[part 1 of 4: packages /cif_swcCanInterface to /cif_swcCanInterface/CANBus_CAN_RT/applicationDataTypes]
AUTOSAR XML (schema 4-1-3)
standard types defined: boolean, float32, float64, sint16, sint32, sint64, sint8, uint16, uint32, uint64, uint8
package /cif_swcCanInterface
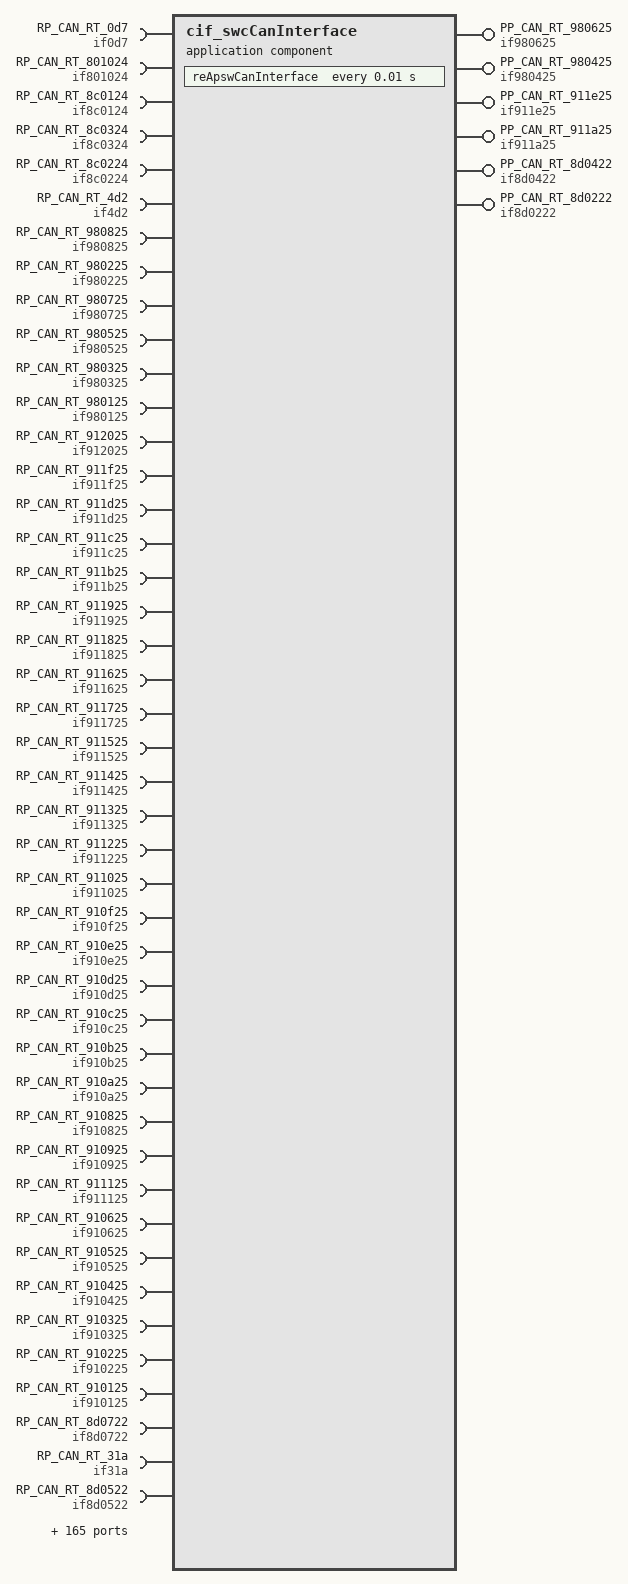
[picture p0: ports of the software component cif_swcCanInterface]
  application sw component type cif_swcCanInterface  # This SW-C may serve as interface to the low level CAN communication. It is connected to the ISignals of the COM component. Its runnable can read and write all in- and output signals and can either process them or delegate them to other SW-Cs
    6 x provide port:
      PP_CAN_RT_980625: provided-interface=if980625  # This is a provided port for all signals of outbound CAN frame RT_IRTemp_Temp_RL_2, 9963045 (0x980625). The data elements of this port will typically be mapped to the related outbound ISignals of the COM component.
      PP_CAN_RT_980425: provided-interface=if980425  # This is a provided port for all signals of outbound CAN frame RT_IRTemp_Temp_FR_2, 9962533 (0x980425). The data elements of this port will typically be mapped to the related outbound ISignals of the COM component.
      PP_CAN_RT_911e25: provided-interface=if911e25  # This is a provided port for all signals of outbound CAN frame RT_IRTemp_Temp_30, 9510437 (0x911e25). The data elements of this port will typically be mapped to the related outbound ISignals of the COM component.
      PP_CAN_RT_911a25: provided-interface=if911a25  # This is a provided port for all signals of outbound CAN frame RT_IRTemp_Temp_26, 9509413 (0x911a25). The data elements of this port will typically be mapped to the related outbound ISignals of the COM component.
      PP_CAN_RT_8d0422: provided-interface=if8d0422  # This is a provided port for all signals of outbound CAN frame RT_SB_Trig_Forward_Dist, 9241634 (0x8d0422). The data elements of this port will typically be mapped to the related outbound ISignals of the COM component.
      PP_CAN_RT_8d0222: provided-interface=if8d0222  # This is a provided port for all signals of outbound CAN frame RT_SB_Trig_Accel, 9241122 (0x8d0222). The data elements of this port will typically be mapped to the related outbound ISignals of the COM component.
    209 x require port:
      RP_CAN_RT_0d7: required-interface=if0d7  # This is a required port for all signals of inbound CAN frame RT_SB_INS_Vel_Body_Axes, 215 (0x0d7). The data elements of this port will typically be mapped to the related inbound ISignals of the COM component.
      RP_CAN_RT_801024: required-interface=if801024  # This is a required port for all signals of inbound CAN frame RT_DL1MK3_Speed, 8392740 (0x801024). The data elements of this port will typically be mapped to the related inbound ISignals of the COM component.
      RP_CAN_RT_8c0124: required-interface=if8c0124  # This is a required port for all signals of inbound CAN frame RT_DL1MK3_GPS_Time, 9175332 (0x8c0124). The data elements of this port will typically be mapped to the related inbound ISignals of the COM component.
      RP_CAN_RT_8c0324: required-interface=if8c0324  # This is a required port for all signals of inbound CAN frame RT_DL1MK3_GPS_Pos_LLH_2, 9175844 (0x8c0324). The data elements of this port will typically be mapped to the related inbound ISignals of the COM component.
      RP_CAN_RT_8c0224: required-interface=if8c0224  # This is a required port for all signals of inbound CAN frame RT_DL1MK3_GPS_Pos_LLH_1, 9175588 (0x8c0224). The data elements of this port will typically be mapped to the related inbound ISignals of the COM component.
      RP_CAN_RT_4d2: required-interface=if4d2  # This is a required port for all signals of inbound CAN frame RT_DL1MK3_GPS_Speed, 1234 (0x4d2). The data elements of this port will typically be mapped to the related inbound ISignals of the COM component.
      RP_CAN_RT_980825: required-interface=if980825  # This is a required port for all signals of inbound CAN frame RT_IRTemp_Temp_RR_2, 9963557 (0x980825). The data elements of this port will typically be mapped to the related inbound ISignals of the COM component.
      RP_CAN_RT_980225: required-interface=if980225  # This is a required port for all signals of inbound CAN frame RT_IRTemp_Temp_FL_2, 9962021 (0x980225). The data elements of this port will typically be mapped to the related inbound ISignals of the COM component.
      RP_CAN_RT_980725: required-interface=if980725  # This is a required port for all signals of inbound CAN frame RT_IRTemp_Temp_RR_1, 9963301 (0x980725). The data elements of this port will typically be mapped to the related inbound ISignals of the COM component.
      RP_CAN_RT_980525: required-interface=if980525  # This is a required port for all signals of inbound CAN frame RT_IRTemp_Temp_RL_1, 9962789 (0x980525). The data elements of this port will typically be mapped to the related inbound ISignals of the COM component.
      RP_CAN_RT_980325: required-interface=if980325  # This is a required port for all signals of inbound CAN frame RT_IRTemp_Temp_FR_1, 9962277 (0x980325). The data elements of this port will typically be mapped to the related inbound ISignals of the COM component.
      RP_CAN_RT_980125: required-interface=if980125  # This is a required port for all signals of inbound CAN frame RT_IRTemp_Temp_FL_1, 9961765 (0x980125). The data elements of this port will typically be mapped to the related inbound ISignals of the COM component.
      RP_CAN_RT_912025: required-interface=if912025  # This is a required port for all signals of inbound CAN frame RT_IRTemp_Temp_32, 9510949 (0x912025). The data elements of this port will typically be mapped to the related inbound ISignals of the COM component.
      RP_CAN_RT_911f25: required-interface=if911f25  # This is a required port for all signals of inbound CAN frame RT_IRTemp_Temp_31, 9510693 (0x911f25). The data elements of this port will typically be mapped to the related inbound ISignals of the COM component.
      RP_CAN_RT_911d25: required-interface=if911d25  # This is a required port for all signals of inbound CAN frame RT_IRTemp_Temp_29, 9510181 (0x911d25). The data elements of this port will typically be mapped to the related inbound ISignals of the COM component.
      RP_CAN_RT_911c25: required-interface=if911c25  # This is a required port for all signals of inbound CAN frame RT_IRTemp_Temp_28, 9509925 (0x911c25). The data elements of this port will typically be mapped to the related inbound ISignals of the COM component.
      RP_CAN_RT_911b25: required-interface=if911b25  # This is a required port for all signals of inbound CAN frame RT_IRTemp_Temp_27, 9509669 (0x911b25). The data elements of this port will typically be mapped to the related inbound ISignals of the COM component.
      RP_CAN_RT_911925: required-interface=if911925  # This is a required port for all signals of inbound CAN frame RT_IRTemp_Temp_25, 9509157 (0x911925). The data elements of this port will typically be mapped to the related inbound ISignals of the COM component.
      RP_CAN_RT_911825: required-interface=if911825  # This is a required port for all signals of inbound CAN frame RT_IRTemp_Temp_24, 9508901 (0x911825). The data elements of this port will typically be mapped to the related inbound ISignals of the COM component.
      RP_CAN_RT_911625: required-interface=if911625  # This is a required port for all signals of inbound CAN frame RT_IRTemp_Temp_22, 9508389 (0x911625). The data elements of this port will typically be mapped to the related inbound ISignals of the COM component.
      RP_CAN_RT_911725: required-interface=if911725  # This is a required port for all signals of inbound CAN frame RT_IRTemp_Temp_23, 9508645 (0x911725). The data elements of this port will typically be mapped to the related inbound ISignals of the COM component.
      RP_CAN_RT_911525: required-interface=if911525  # This is a required port for all signals of inbound CAN frame RT_IRTemp_Temp_21, 9508133 (0x911525). The data elements of this port will typically be mapped to the related inbound ISignals of the COM component.
      RP_CAN_RT_911425: required-interface=if911425  # This is a required port for all signals of inbound CAN frame RT_IRTemp_Temp_20, 9507877 (0x911425). The data elements of this port will typically be mapped to the related inbound ISignals of the COM component.
      RP_CAN_RT_911325: required-interface=if911325  # This is a required port for all signals of inbound CAN frame RT_IRTemp_Temp_19, 9507621 (0x911325). The data elements of this port will typically be mapped to the related inbound ISignals of the COM component.
      RP_CAN_RT_911225: required-interface=if911225  # This is a required port for all signals of inbound CAN frame RT_IRTemp_Temp_18, 9507365 (0x911225). The data elements of this port will typically be mapped to the related inbound ISignals of the COM component.
      RP_CAN_RT_911025: required-interface=if911025  # This is a required port for all signals of inbound CAN frame RT_IRTemp_Temp_16, 9506853 (0x911025). The data elements of this port will typically be mapped to the related inbound ISignals of the COM component.
      RP_CAN_RT_910f25: required-interface=if910f25  # This is a required port for all signals of inbound CAN frame RT_IRTemp_Temp_15, 9506597 (0x910f25). The data elements of this port will typically be mapped to the related inbound ISignals of the COM component.
      RP_CAN_RT_910e25: required-interface=if910e25  # This is a required port for all signals of inbound CAN frame RT_IRTemp_Temp_14, 9506341 (0x910e25). The data elements of this port will typically be mapped to the related inbound ISignals of the COM component.
      RP_CAN_RT_910d25: required-interface=if910d25  # This is a required port for all signals of inbound CAN frame RT_IRTemp_Temp_13, 9506085 (0x910d25). The data elements of this port will typically be mapped to the related inbound ISignals of the COM component.
      RP_CAN_RT_910c25: required-interface=if910c25  # This is a required port for all signals of inbound CAN frame RT_IRTemp_Temp_12, 9505829 (0x910c25). The data elements of this port will typically be mapped to the related inbound ISignals of the COM component.
      RP_CAN_RT_910b25: required-interface=if910b25  # This is a required port for all signals of inbound CAN frame RT_IRTemp_Temp_11, 9505573 (0x910b25). The data elements of this port will typically be mapped to the related inbound ISignals of the COM component.
      RP_CAN_RT_910a25: required-interface=if910a25  # This is a required port for all signals of inbound CAN frame RT_IRTemp_Temp_10, 9505317 (0x910a25). The data elements of this port will typically be mapped to the related inbound ISignals of the COM component.
      RP_CAN_RT_910825: required-interface=if910825  # This is a required port for all signals of inbound CAN frame RT_IRTemp_Temp_8, 9504805 (0x910825). The data elements of this port will typically be mapped to the related inbound ISignals of the COM component.
      RP_CAN_RT_910925: required-interface=if910925  # This is a required port for all signals of inbound CAN frame RT_IRTemp_Temp_9, 9505061 (0x910925). The data elements of this port will typically be mapped to the related inbound ISignals of the COM component.
      RP_CAN_RT_911125: required-interface=if911125  # This is a required port for all signals of inbound CAN frame RT_IRTemp_Temp_17, 9507109 (0x911125). The data elements of this port will typically be mapped to the related inbound ISignals of the COM component.
      RP_CAN_RT_910625: required-interface=if910625  # This is a required port for all signals of inbound CAN frame RT_IRTemp_Temp_6, 9504293 (0x910625). The data elements of this port will typically be mapped to the related inbound ISignals of the COM component.
      RP_CAN_RT_910525: required-interface=if910525  # This is a required port for all signals of inbound CAN frame RT_IRTemp_Temp_5, 9504037 (0x910525). The data elements of this port will typically be mapped to the related inbound ISignals of the COM component.
      RP_CAN_RT_910425: required-interface=if910425  # This is a required port for all signals of inbound CAN frame RT_IRTemp_Temp_4, 9503781 (0x910425). The data elements of this port will typically be mapped to the related inbound ISignals of the COM component.
      RP_CAN_RT_910325: required-interface=if910325  # This is a required port for all signals of inbound CAN frame RT_IRTemp_Temp_3, 9503525 (0x910325). The data elements of this port will typically be mapped to the related inbound ISignals of the COM component.
      RP_CAN_RT_910225: required-interface=if910225  # This is a required port for all signals of inbound CAN frame RT_IRTemp_Temp_2, 9503269 (0x910225). The data elements of this port will typically be mapped to the related inbound ISignals of the COM component.
      RP_CAN_RT_910125: required-interface=if910125  # This is a required port for all signals of inbound CAN frame RT_IRTemp_Temp_1, 9503013 (0x910125). The data elements of this port will typically be mapped to the related inbound ISignals of the COM component.
      RP_CAN_RT_8d0722: required-interface=if8d0722  # This is a required port for all signals of inbound CAN frame RT_SB_Trig_Final_Condition, 9242402 (0x8d0722). The data elements of this port will typically be mapped to the related inbound ISignals of the COM component.
      RP_CAN_RT_31a: required-interface=if31a  # This is a required port for all signals of inbound CAN frame RT_SB_Trig_Initial_Condition, 794 (0x31a). The data elements of this port will typically be mapped to the related inbound ISignals of the COM component.
      RP_CAN_RT_8d0522: required-interface=if8d0522  # This is a required port for all signals of inbound CAN frame RT_SB_Trig_Direct_Dist, 9241890 (0x8d0522). The data elements of this port will typically be mapped to the related inbound ISignals of the COM component.
      RP_CAN_RT_8d0322: required-interface=if8d0322  # This is a required port for all signals of inbound CAN frame RT_SB_Trig_Path_Dist, 9241378 (0x8d0322). The data elements of this port will typically be mapped to the related inbound ISignals of the COM component.
      RP_CAN_RT_960b24: required-interface=if960b24  # This is a required port for all signals of inbound CAN frame RT_DL1MK3_Measure_Time_11, 9833252 (0x960b24). The data elements of this port will typically be mapped to the related inbound ISignals of the COM component.
      RP_CAN_RT_960a24: required-interface=if960a24  # This is a required port for all signals of inbound CAN frame RT_DL1MK3_Measure_Time_10, 9832996 (0x960a24). The data elements of this port will typically be mapped to the related inbound ISignals of the COM component.
      RP_CAN_RT_960924: required-interface=if960924  # This is a required port for all signals of inbound CAN frame RT_DL1MK3_Measure_Time_9, 9832740 (0x960924). The data elements of this port will typically be mapped to the related inbound ISignals of the COM component.
      RP_CAN_RT_960824: required-interface=if960824  # This is a required port for all signals of inbound CAN frame RT_DL1MK3_Measure_Time_8, 9832484 (0x960824). The data elements of this port will typically be mapped to the related inbound ISignals of the COM component.
      RP_CAN_RT_960724: required-interface=if960724  # This is a required port for all signals of inbound CAN frame RT_DL1MK3_Measure_Time_7, 9832228 (0x960724). The data elements of this port will typically be mapped to the related inbound ISignals of the COM component.
      RP_CAN_RT_960624: required-interface=if960624  # This is a required port for all signals of inbound CAN frame RT_DL1MK3_Measure_Time_6, 9831972 (0x960624). The data elements of this port will typically be mapped to the related inbound ISignals of the COM component.
      RP_CAN_RT_960524: required-interface=if960524  # This is a required port for all signals of inbound CAN frame RT_DL1MK3_Measure_Time_5, 9831716 (0x960524). The data elements of this port will typically be mapped to the related inbound ISignals of the COM component.
      RP_CAN_RT_960424: required-interface=if960424  # This is a required port for all signals of inbound CAN frame RT_DL1MK3_Measure_Time_4, 9831460 (0x960424). The data elements of this port will typically be mapped to the related inbound ISignals of the COM component.
      RP_CAN_RT_960324: required-interface=if960324  # This is a required port for all signals of inbound CAN frame RT_DL1MK3_Measure_Time_3, 9831204 (0x960324). The data elements of this port will typically be mapped to the related inbound ISignals of the COM component.
      RP_CAN_RT_960224: required-interface=if960224  # This is a required port for all signals of inbound CAN frame RT_DL1MK3_Measure_Time_2, 9830948 (0x960224). The data elements of this port will typically be mapped to the related inbound ISignals of the COM component.
      RP_CAN_RT_960124: required-interface=if960124  # This is a required port for all signals of inbound CAN frame RT_DL1MK3_Measure_Time_1, 9830692 (0x960124). The data elements of this port will typically be mapped to the related inbound ISignals of the COM component.
      RP_CAN_RT_950c24: required-interface=if950c24  # This is a required port for all signals of inbound CAN frame RT_DL1MK3_RPM, 9767972 (0x950c24). The data elements of this port will typically be mapped to the related inbound ISignals of the COM component.
      RP_CAN_RT_950b24: required-interface=if950b24  # This is a required port for all signals of inbound CAN frame RT_DL1MK3_Freq_4, 9767716 (0x950b24). The data elements of this port will typically be mapped to the related inbound ISignals of the COM component.
      RP_CAN_RT_950a24: required-interface=if950a24  # This is a required port for all signals of inbound CAN frame RT_DL1MK3_Freq_3, 9767460 (0x950a24). The data elements of this port will typically be mapped to the related inbound ISignals of the COM component.
      RP_CAN_RT_950924: required-interface=if950924  # This is a required port for all signals of inbound CAN frame RT_DL1MK3_Freq_2, 9767204 (0x950924). The data elements of this port will typically be mapped to the related inbound ISignals of the COM component.
      RP_CAN_RT_970324: required-interface=if970324  # This is a required port for all signals of inbound CAN frame RT_DL1MK3_Misc_3, 9896740 (0x970324). The data elements of this port will typically be mapped to the related inbound ISignals of the COM component.
      RP_CAN_RT_970224: required-interface=if970224  # This is a required port for all signals of inbound CAN frame RT_DL1MK3_Misc_2, 9896484 (0x970224). The data elements of this port will typically be mapped to the related inbound ISignals of the COM component.
      RP_CAN_RT_970124: required-interface=if970124  # This is a required port for all signals of inbound CAN frame RT_DL1MK3_Misc_1, 9896228 (0x970124). The data elements of this port will typically be mapped to the related inbound ISignals of the COM component.
      RP_CAN_RT_941f24: required-interface=if941f24  # This is a required port for all signals of inbound CAN frame RT_DL1MK3_Aux_31, 9707300 (0x941f24). The data elements of this port will typically be mapped to the related inbound ISignals of the COM component.
      RP_CAN_RT_941e24: required-interface=if941e24  # This is a required port for all signals of inbound CAN frame RT_DL1MK3_Aux_30, 9707044 (0x941e24). The data elements of this port will typically be mapped to the related inbound ISignals of the COM component.
      RP_CAN_RT_941d24: required-interface=if941d24  # This is a required port for all signals of inbound CAN frame RT_DL1MK3_Aux_29, 9706788 (0x941d24). The data elements of this port will typically be mapped to the related inbound ISignals of the COM component.
      RP_CAN_RT_941c24: required-interface=if941c24  # This is a required port for all signals of inbound CAN frame RT_DL1MK3_Aux_28, 9706532 (0x941c24). The data elements of this port will typically be mapped to the related inbound ISignals of the COM component.
      RP_CAN_RT_941b24: required-interface=if941b24  # This is a required port for all signals of inbound CAN frame RT_DL1MK3_Aux_27, 9706276 (0x941b24). The data elements of this port will typically be mapped to the related inbound ISignals of the COM component.
      RP_CAN_RT_941a24: required-interface=if941a24  # This is a required port for all signals of inbound CAN frame RT_DL1MK3_Aux_26, 9706020 (0x941a24). The data elements of this port will typically be mapped to the related inbound ISignals of the COM component.
      RP_CAN_RT_941924: required-interface=if941924  # This is a required port for all signals of inbound CAN frame RT_DL1MK3_Aux_25, 9705764 (0x941924). The data elements of this port will typically be mapped to the related inbound ISignals of the COM component.
      RP_CAN_RT_941824: required-interface=if941824  # This is a required port for all signals of inbound CAN frame RT_DL1MK3_Aux_24, 9705508 (0x941824). The data elements of this port will typically be mapped to the related inbound ISignals of the COM component.
      RP_CAN_RT_941724: required-interface=if941724  # This is a required port for all signals of inbound CAN frame RT_DL1MK3_Aux_23, 9705252 (0x941724). The data elements of this port will typically be mapped to the related inbound ISignals of the COM component.
      RP_CAN_RT_941624: required-interface=if941624  # This is a required port for all signals of inbound CAN frame RT_DL1MK3_Aux_22, 9704996 (0x941624). The data elements of this port will typically be mapped to the related inbound ISignals of the COM component.
      RP_CAN_RT_941524: required-interface=if941524  # This is a required port for all signals of inbound CAN frame RT_DL1MK3_Aux_21, 9704740 (0x941524). The data elements of this port will typically be mapped to the related inbound ISignals of the COM component.
      RP_CAN_RT_941424: required-interface=if941424  # This is a required port for all signals of inbound CAN frame RT_DL1MK3_Aux_20, 9704484 (0x941424). The data elements of this port will typically be mapped to the related inbound ISignals of the COM component.
      RP_CAN_RT_941324: required-interface=if941324  # This is a required port for all signals of inbound CAN frame RT_DL1MK3_Aux_19, 9704228 (0x941324). The data elements of this port will typically be mapped to the related inbound ISignals of the COM component.
      RP_CAN_RT_941224: required-interface=if941224  # This is a required port for all signals of inbound CAN frame RT_DL1MK3_Aux_18, 9703972 (0x941224). The data elements of this port will typically be mapped to the related inbound ISignals of the COM component.
      RP_CAN_RT_941124: required-interface=if941124  # This is a required port for all signals of inbound CAN frame RT_DL1MK3_Aux_17, 9703716 (0x941124). The data elements of this port will typically be mapped to the related inbound ISignals of the COM component.
      RP_CAN_RT_941024: required-interface=if941024  # This is a required port for all signals of inbound CAN frame RT_DL1MK3_Aux_16, 9703460 (0x941024). The data elements of this port will typically be mapped to the related inbound ISignals of the COM component.
      RP_CAN_RT_940f24: required-interface=if940f24  # This is a required port for all signals of inbound CAN frame RT_DL1MK3_Aux_15, 9703204 (0x940f24). The data elements of this port will typically be mapped to the related inbound ISignals of the COM component.
      RP_CAN_RT_940e24: required-interface=if940e24  # This is a required port for all signals of inbound CAN frame RT_DL1MK3_Aux_14, 9702948 (0x940e24). The data elements of this port will typically be mapped to the related inbound ISignals of the COM component.
      RP_CAN_RT_940d24: required-interface=if940d24  # This is a required port for all signals of inbound CAN frame RT_DL1MK3_Aux_13, 9702692 (0x940d24). The data elements of this port will typically be mapped to the related inbound ISignals of the COM component.
      RP_CAN_RT_940c24: required-interface=if940c24  # This is a required port for all signals of inbound CAN frame RT_DL1MK3_Aux_12, 9702436 (0x940c24). The data elements of this port will typically be mapped to the related inbound ISignals of the COM component.
      RP_CAN_RT_940b24: required-interface=if940b24  # This is a required port for all signals of inbound CAN frame RT_DL1MK3_Aux_11, 9702180 (0x940b24). The data elements of this port will typically be mapped to the related inbound ISignals of the COM component.
      RP_CAN_RT_940924: required-interface=if940924  # This is a required port for all signals of inbound CAN frame RT_DL1MK3_Aux_9, 9701668 (0x940924). The data elements of this port will typically be mapped to the related inbound ISignals of the COM component.
      RP_CAN_RT_940a24: required-interface=if940a24  # This is a required port for all signals of inbound CAN frame RT_DL1MK3_Aux_10, 9701924 (0x940a24). The data elements of this port will typically be mapped to the related inbound ISignals of the COM component.
      RP_CAN_RT_940824: required-interface=if940824  # This is a required port for all signals of inbound CAN frame RT_DL1MK3_Aux_8, 9701412 (0x940824). The data elements of this port will typically be mapped to the related inbound ISignals of the COM component.
      RP_CAN_RT_940724: required-interface=if940724  # This is a required port for all signals of inbound CAN frame RT_DL1MK3_Aux_7, 9701156 (0x940724). The data elements of this port will typically be mapped to the related inbound ISignals of the COM component.
      RP_CAN_RT_940624: required-interface=if940624  # This is a required port for all signals of inbound CAN frame RT_DL1MK3_Aux_6, 9700900 (0x940624). The data elements of this port will typically be mapped to the related inbound ISignals of the COM component.
      RP_CAN_RT_940524: required-interface=if940524  # This is a required port for all signals of inbound CAN frame RT_DL1MK3_Aux_5, 9700644 (0x940524). The data elements of this port will typically be mapped to the related inbound ISignals of the COM component.
      RP_CAN_RT_940424: required-interface=if940424  # This is a required port for all signals of inbound CAN frame RT_DL1MK3_Aux_4, 9700388 (0x940424). The data elements of this port will typically be mapped to the related inbound ISignals of the COM component.
      RP_CAN_RT_940324: required-interface=if940324  # This is a required port for all signals of inbound CAN frame RT_DL1MK3_Aux_3, 9700132 (0x940324). The data elements of this port will typically be mapped to the related inbound ISignals of the COM component.
      RP_CAN_RT_940224: required-interface=if940224  # This is a required port for all signals of inbound CAN frame RT_DL1MK3_Aux_2, 9699876 (0x940224). The data elements of this port will typically be mapped to the related inbound ISignals of the COM component.
      RP_CAN_RT_940124: required-interface=if940124  # This is a required port for all signals of inbound CAN frame RT_DL1MK3_Aux_1, 9699620 (0x940124). The data elements of this port will typically be mapped to the related inbound ISignals of the COM component.
      RP_CAN_RT_900524: required-interface=if900524  # This is a required port for all signals of inbound CAN frame RT_DL1MK3_Pressure_5, 9438500 (0x900524). The data elements of this port will typically be mapped to the related inbound ISignals of the COM component.
      RP_CAN_RT_900424: required-interface=if900424  # This is a required port for all signals of inbound CAN frame RT_DL1MK3_Pressure_4, 9438244 (0x900424). The data elements of this port will typically be mapped to the related inbound ISignals of the COM component.
      RP_CAN_RT_900324: required-interface=if900324  # This is a required port for all signals of inbound CAN frame RT_DL1MK3_Pressure_3, 9437988 (0x900324). The data elements of this port will typically be mapped to the related inbound ISignals of the COM component.
      RP_CAN_RT_900224: required-interface=if900224  # This is a required port for all signals of inbound CAN frame RT_DL1MK3_Pressure_2, 9437732 (0x900224). The data elements of this port will typically be mapped to the related inbound ISignals of the COM component.
      RP_CAN_RT_900124: required-interface=if900124  # This is a required port for all signals of inbound CAN frame RT_DL1MK3_Pressure_1, 9437476 (0x900124). The data elements of this port will typically be mapped to the related inbound ISignals of the COM component.
      RP_CAN_RT_920324: required-interface=if920324  # This is a required port for all signals of inbound CAN frame RT_DL1MK3_Angle_3, 9569060 (0x920324). The data elements of this port will typically be mapped to the related inbound ISignals of the COM component.
      RP_CAN_RT_920224: required-interface=if920224  # This is a required port for all signals of inbound CAN frame RT_DL1MK3_Angle_2, 9568804 (0x920224). The data elements of this port will typically be mapped to the related inbound ISignals of the COM component.
      RP_CAN_RT_920124: required-interface=if920124  # This is a required port for all signals of inbound CAN frame RT_DL1MK3_Angle_1, 9568548 (0x920124). The data elements of this port will typically be mapped to the related inbound ISignals of the COM component.
      RP_CAN_RT_911924: required-interface=if911924  # This is a required port for all signals of inbound CAN frame RT_DL1MK3_Temp_25, 9509156 (0x911924). The data elements of this port will typically be mapped to the related inbound ISignals of the COM component.
      RP_CAN_RT_911824: required-interface=if911824  # This is a required port for all signals of inbound CAN frame RT_DL1MK3_Temp_24, 9508900 (0x911824). The data elements of this port will typically be mapped to the related inbound ISignals of the COM component.
      RP_CAN_RT_911724: required-interface=if911724  # This is a required port for all signals of inbound CAN frame RT_DL1MK3_Temp_23, 9508644 (0x911724). The data elements of this port will typically be mapped to the related inbound ISignals of the COM component.
      RP_CAN_RT_911624: required-interface=if911624  # This is a required port for all signals of inbound CAN frame RT_DL1MK3_Temp_22, 9508388 (0x911624). The data elements of this port will typically be mapped to the related inbound ISignals of the COM component.
      RP_CAN_RT_911524: required-interface=if911524  # This is a required port for all signals of inbound CAN frame RT_DL1MK3_Temp_21, 9508132 (0x911524). The data elements of this port will typically be mapped to the related inbound ISignals of the COM component.
      RP_CAN_RT_911424: required-interface=if911424  # This is a required port for all signals of inbound CAN frame RT_DL1MK3_Temp_20, 9507876 (0x911424). The data elements of this port will typically be mapped to the related inbound ISignals of the COM component.
      RP_CAN_RT_911324: required-interface=if911324  # This is a required port for all signals of inbound CAN frame RT_DL1MK3_Temp_19, 9507620 (0x911324). The data elements of this port will typically be mapped to the related inbound ISignals of the COM component.
      RP_CAN_RT_911224: required-interface=if911224  # This is a required port for all signals of inbound CAN frame RT_DL1MK3_Temp_18, 9507364 (0x911224). The data elements of this port will typically be mapped to the related inbound ISignals of the COM component.
      RP_CAN_RT_911124: required-interface=if911124  # This is a required port for all signals of inbound CAN frame RT_DL1MK3_Temp_17, 9507108 (0x911124). The data elements of this port will typically be mapped to the related inbound ISignals of the COM component.
      RP_CAN_RT_911024: required-interface=if911024  # This is a required port for all signals of inbound CAN frame RT_DL1MK3_Temp_16, 9506852 (0x911024). The data elements of this port will typically be mapped to the related inbound ISignals of the COM component.
      RP_CAN_RT_910f24: required-interface=if910f24  # This is a required port for all signals of inbound CAN frame RT_DL1MK3_Temp_15, 9506596 (0x910f24). The data elements of this port will typically be mapped to the related inbound ISignals of the COM component.
      RP_CAN_RT_910e24: required-interface=if910e24  # This is a required port for all signals of inbound CAN frame RT_DL1MK3_Temp_14, 9506340 (0x910e24). The data elements of this port will typically be mapped to the related inbound ISignals of the COM component.
      RP_CAN_RT_910d24: required-interface=if910d24  # This is a required port for all signals of inbound CAN frame RT_DL1MK3_Temp_13, 9506084 (0x910d24). The data elements of this port will typically be mapped to the related inbound ISignals of the COM component.
      RP_CAN_RT_910c24: required-interface=if910c24  # This is a required port for all signals of inbound CAN frame RT_DL1MK3_Temp_12, 9505828 (0x910c24). The data elements of this port will typically be mapped to the related inbound ISignals of the COM component.
      RP_CAN_RT_910b24: required-interface=if910b24  # This is a required port for all signals of inbound CAN frame RT_DL1MK3_Temp_11, 9505572 (0x910b24). The data elements of this port will typically be mapped to the related inbound ISignals of the COM component.
      RP_CAN_RT_910a24: required-interface=if910a24  # This is a required port for all signals of inbound CAN frame RT_DL1MK3_Temp_10, 9505316 (0x910a24). The data elements of this port will typically be mapped to the related inbound ISignals of the COM component.
      RP_CAN_RT_910924: required-interface=if910924  # This is a required port for all signals of inbound CAN frame RT_DL1MK3_Temp_9, 9505060 (0x910924). The data elements of this port will typically be mapped to the related inbound ISignals of the COM component.
      RP_CAN_RT_910824: required-interface=if910824  # This is a required port for all signals of inbound CAN frame RT_DL1MK3_Temp_8, 9504804 (0x910824). The data elements of this port will typically be mapped to the related inbound ISignals of the COM component.
      RP_CAN_RT_910724: required-interface=if910724  # This is a required port for all signals of inbound CAN frame RT_DL1MK3_Temp_7, 9504548 (0x910724). The data elements of this port will typically be mapped to the related inbound ISignals of the COM component.
      RP_CAN_RT_910624: required-interface=if910624  # This is a required port for all signals of inbound CAN frame RT_DL1MK3_Temp_6, 9504292 (0x910624). The data elements of this port will typically be mapped to the related inbound ISignals of the COM component.
      RP_CAN_RT_910524: required-interface=if910524  # This is a required port for all signals of inbound CAN frame RT_DL1MK3_Temp_5, 9504036 (0x910524). The data elements of this port will typically be mapped to the related inbound ISignals of the COM component.
      RP_CAN_RT_910424: required-interface=if910424  # This is a required port for all signals of inbound CAN frame RT_DL1MK3_Temp_4, 9503780 (0x910424). The data elements of this port will typically be mapped to the related inbound ISignals of the COM component.
      RP_CAN_RT_910324: required-interface=if910324  # This is a required port for all signals of inbound CAN frame RT_DL1MK3_Temp_3, 9503524 (0x910324). The data elements of this port will typically be mapped to the related inbound ISignals of the COM component.
      RP_CAN_RT_910224: required-interface=if910224  # This is a required port for all signals of inbound CAN frame RT_DL1MK3_Temp_2, 9503268 (0x910224). The data elements of this port will typically be mapped to the related inbound ISignals of the COM component.
      RP_CAN_RT_910124: required-interface=if910124  # This is a required port for all signals of inbound CAN frame RT_DL1MK3_Temp_1, 9503012 (0x910124). The data elements of this port will typically be mapped to the related inbound ISignals of the COM component.
      RP_CAN_RT_821f24: required-interface=if821f24  # This is a required port for all signals of inbound CAN frame RT_DL1MK3_Analog_32, 8527652 (0x821f24). The data elements of this port will typically be mapped to the related inbound ISignals of the COM component.
      RP_CAN_RT_821e24: required-interface=if821e24  # This is a required port for all signals of inbound CAN frame RT_DL1MK3_Analog_31, 8527396 (0x821e24). The data elements of this port will typically be mapped to the related inbound ISignals of the COM component.
      RP_CAN_RT_821d24: required-interface=if821d24  # This is a required port for all signals of inbound CAN frame RT_DL1MK3_Analog_30, 8527140 (0x821d24). The data elements of this port will typically be mapped to the related inbound ISignals of the COM component.
      RP_CAN_RT_821c24: required-interface=if821c24  # This is a required port for all signals of inbound CAN frame RT_DL1MK3_Analog_29, 8526884 (0x821c24). The data elements of this port will typically be mapped to the related inbound ISignals of the COM component.
      RP_CAN_RT_821b24: required-interface=if821b24  # This is a required port for all signals of inbound CAN frame RT_DL1MK3_Analog_28, 8526628 (0x821b24). The data elements of this port will typically be mapped to the related inbound ISignals of the COM component.
      RP_CAN_RT_821a24: required-interface=if821a24  # This is a required port for all signals of inbound CAN frame RT_DL1MK3_Analog_27, 8526372 (0x821a24). The data elements of this port will typically be mapped to the related inbound ISignals of the COM component.
      RP_CAN_RT_821924: required-interface=if821924  # This is a required port for all signals of inbound CAN frame RT_DL1MK3_Analog_26, 8526116 (0x821924). The data elements of this port will typically be mapped to the related inbound ISignals of the COM component.
      RP_CAN_RT_821824: required-interface=if821824  # This is a required port for all signals of inbound CAN frame RT_DL1MK3_Analog_25, 8525860 (0x821824). The data elements of this port will typically be mapped to the related inbound ISignals of the COM component.
      RP_CAN_RT_820e24: required-interface=if820e24  # This is a required port for all signals of inbound CAN frame RT_DL1MK3_Analog_15, 8523300 (0x820e24). The data elements of this port will typically be mapped to the related inbound ISignals of the COM component.
      RP_CAN_RT_820d24: required-interface=if820d24  # This is a required port for all signals of inbound CAN frame RT_DL1MK3_Analog_14, 8523044 (0x820d24). The data elements of this port will typically be mapped to the related inbound ISignals of the COM component.
      RP_CAN_RT_821024: required-interface=if821024  # This is a required port for all signals of inbound CAN frame RT_DL1MK3_Analog_17, 8523812 (0x821024). The data elements of this port will typically be mapped to the related inbound ISignals of the COM component.
      RP_CAN_RT_821724: required-interface=if821724  # This is a required port for all signals of inbound CAN frame RT_DL1MK3_Analog_24, 8525604 (0x821724). The data elements of this port will typically be mapped to the related inbound ISignals of the COM component.
      RP_CAN_RT_821624: required-interface=if821624  # This is a required port for all signals of inbound CAN frame RT_DL1MK3_Analog_23, 8525348 (0x821624). The data elements of this port will typically be mapped to the related inbound ISignals of the COM component.
      RP_CAN_RT_821524: required-interface=if821524  # This is a required port for all signals of inbound CAN frame RT_DL1MK3_Analog_22, 8525092 (0x821524). The data elements of this port will typically be mapped to the related inbound ISignals of the COM component.
      RP_CAN_RT_821424: required-interface=if821424  # This is a required port for all signals of inbound CAN frame RT_DL1MK3_Analog_21, 8524836 (0x821424). The data elements of this port will typically be mapped to the related inbound ISignals of the COM component.
      RP_CAN_RT_821324: required-interface=if821324  # This is a required port for all signals of inbound CAN frame RT_DL1MK3_Analog_20, 8524580 (0x821324). The data elements of this port will typically be mapped to the related inbound ISignals of the COM component.
      RP_CAN_RT_821224: required-interface=if821224  # This is a required port for all signals of inbound CAN frame RT_DL1MK3_Analog_19, 8524324 (0x821224). The data elements of this port will typically be mapped to the related inbound ISignals of the COM component.
      RP_CAN_RT_820f24: required-interface=if820f24  # This is a required port for all signals of inbound CAN frame RT_DL1MK3_Analog_16, 8523556 (0x820f24). The data elements of this port will typically be mapped to the related inbound ISignals of the COM component.
      RP_CAN_RT_821124: required-interface=if821124  # This is a required port for all signals of inbound CAN frame RT_DL1MK3_Analog_18, 8524068 (0x821124). The data elements of this port will typically be mapped to the related inbound ISignals of the COM component.
      RP_CAN_RT_820b24: required-interface=if820b24  # This is a required port for all signals of inbound CAN frame RT_DL1MK3_Analog_12, 8522532 (0x820b24). The data elements of this port will typically be mapped to the related inbound ISignals of the COM component.
      RP_CAN_RT_820a24: required-interface=if820a24  # This is a required port for all signals of inbound CAN frame RT_DL1MK3_Analog_11, 8522276 (0x820a24). The data elements of this port will typically be mapped to the related inbound ISignals of the COM component.
      RP_CAN_RT_820924: required-interface=if820924  # This is a required port for all signals of inbound CAN frame RT_DL1MK3_Analog_10, 8522020 (0x820924). The data elements of this port will typically be mapped to the related inbound ISignals of the COM component.
      RP_CAN_RT_820824: required-interface=if820824  # This is a required port for all signals of inbound CAN frame RT_DL1MK3_Analog_9, 8521764 (0x820824). The data elements of this port will typically be mapped to the related inbound ISignals of the COM component.
      RP_CAN_RT_820724: required-interface=if820724  # This is a required port for all signals of inbound CAN frame RT_DL1MK3_Analog_8, 8521508 (0x820724). The data elements of this port will typically be mapped to the related inbound ISignals of the COM component.
      RP_CAN_RT_820624: required-interface=if820624  # This is a required port for all signals of inbound CAN frame RT_DL1MK3_Analog_7, 8521252 (0x820624). The data elements of this port will typically be mapped to the related inbound ISignals of the COM component.
      RP_CAN_RT_820524: required-interface=if820524  # This is a required port for all signals of inbound CAN frame RT_DL1MK3_Analog_6, 8520996 (0x820524). The data elements of this port will typically be mapped to the related inbound ISignals of the COM component.
      RP_CAN_RT_820424: required-interface=if820424  # This is a required port for all signals of inbound CAN frame RT_DL1MK3_Analog_5, 8520740 (0x820424). The data elements of this port will typically be mapped to the related inbound ISignals of the COM component.
      RP_CAN_RT_820324: required-interface=if820324  # This is a required port for all signals of inbound CAN frame RT_DL1MK3_Analog_4, 8520484 (0x820324). The data elements of this port will typically be mapped to the related inbound ISignals of the COM component.
      RP_CAN_RT_820224: required-interface=if820224  # This is a required port for all signals of inbound CAN frame RT_DL1MK3_Analog_3, 8520228 (0x820224). The data elements of this port will typically be mapped to the related inbound ISignals of the COM component.
      RP_CAN_RT_820124: required-interface=if820124  # This is a required port for all signals of inbound CAN frame RT_DL1MK3_Analog_2, 8519972 (0x820124). The data elements of this port will typically be mapped to the related inbound ISignals of the COM component.
      RP_CAN_RT_820024: required-interface=if820024  # This is a required port for all signals of inbound CAN frame RT_DL1MK3_Analog_1, 8519716 (0x820024). The data elements of this port will typically be mapped to the related inbound ISignals of the COM component.
      RP_CAN_RT_800024: required-interface=if800024  # This is a required port for all signals of inbound CAN frame RT_DL1MK3_Accel, 8388644 (0x800024). The data elements of this port will typically be mapped to the related inbound ISignals of the COM component.
      RP_CAN_RT_8f3222: required-interface=if8f3222  # This is a required port for all signals of inbound CAN frame RT_SB_INS_Vpt_4_Vel_NED_2, 9384482 (0x8f3222). The data elements of this port will typically be mapped to the related inbound ISignals of the COM component.
      RP_CAN_RT_8f3122: required-interface=if8f3122  # This is a required port for all signals of inbound CAN frame RT_SB_INS_Vpt_4_Vel_NED_1, 9384226 (0x8f3122). The data elements of this port will typically be mapped to the related inbound ISignals of the COM component.
      RP_CAN_RT_8f3022: required-interface=if8f3022  # This is a required port for all signals of inbound CAN frame RT_SB_INS_Vpt_4_Offset, 9383970 (0x8f3022). The data elements of this port will typically be mapped to the related inbound ISignals of the COM component.
      RP_CAN_RT_8f2222: required-interface=if8f2222  # This is a required port for all signals of inbound CAN frame RT_SB_INS_Vpt_3_Vel_NED_2, 9380386 (0x8f2222). The data elements of this port will typically be mapped to the related inbound ISignals of the COM component.
      RP_CAN_RT_8f2122: required-interface=if8f2122  # This is a required port for all signals of inbound CAN frame RT_SB_INS_Vpt_3_Vel_NED_1, 9380130 (0x8f2122). The data elements of this port will typically be mapped to the related inbound ISignals of the COM component.
      RP_CAN_RT_8f2022: required-interface=if8f2022  # This is a required port for all signals of inbound CAN frame RT_SB_INS_Vpt_3_Offset, 9379874 (0x8f2022). The data elements of this port will typically be mapped to the related inbound ISignals of the COM component.
      RP_CAN_RT_8f1222: required-interface=if8f1222  # This is a required port for all signals of inbound CAN frame RT_SB_INS_Vpt_2_Vel_NED_2, 9376290 (0x8f1222). The data elements of this port will typically be mapped to the related inbound ISignals of the COM component.
      RP_CAN_RT_8f1122: required-interface=if8f1122  # This is a required port for all signals of inbound CAN frame RT_SB_INS_Vpt_2_Vel_NED_1, 9376034 (0x8f1122). The data elements of this port will typically be mapped to the related inbound ISignals of the COM component.
      RP_CAN_RT_8f1022: required-interface=if8f1022  # This is a required port for all signals of inbound CAN frame RT_SB_INS_Vpt_2_Offset, 9375778 (0x8f1022). The data elements of this port will typically be mapped to the related inbound ISignals of the COM component.
      RP_CAN_RT_8f0222: required-interface=if8f0222  # This is a required port for all signals of inbound CAN frame RT_SB_INS_Vpt_1_Vel_NED_2, 9372194 (0x8f0222). The data elements of this port will typically be mapped to the related inbound ISignals of the COM component.
      RP_CAN_RT_8f0122: required-interface=if8f0122  # This is a required port for all signals of inbound CAN frame RT_SB_INS_Vpt_1_Vel_NED_1, 9371938 (0x8f0122). The data elements of this port will typically be mapped to the related inbound ISignals of the COM component.
      RP_CAN_RT_8f0022: required-interface=if8f0022  # This is a required port for all signals of inbound CAN frame RT_SB_INS_Vpt_1_Offset, 9371682 (0x8f0022). The data elements of this port will typically be mapped to the related inbound ISignals of the COM component.
      RP_CAN_RT_8e1622: required-interface=if8e1622  # This is a required port for all signals of inbound CAN frame RT_SB_INS_Slip, 9311778 (0x8e1622). The data elements of this port will typically be mapped to the related inbound ISignals of the COM component.
      RP_CAN_RT_8e1322: required-interface=if8e1322  # This is a required port for all signals of inbound CAN frame RT_SB_INS_Vel_ECEF_2, 9311010 (0x8e1322). The data elements of this port will typically be mapped to the related inbound ISignals of the COM component.
      RP_CAN_RT_8e1222: required-interface=if8e1222  # This is a required port for all signals of inbound CAN frame RT_SB_INS_Vel_ECEF_1, 9310754 (0x8e1222). The data elements of this port will typically be mapped to the related inbound ISignals of the COM component.
      RP_CAN_RT_8e1122: required-interface=if8e1122  # This is a required port for all signals of inbound CAN frame RT_SB_INS_Vel_NED_2, 9310498 (0x8e1122). The data elements of this port will typically be mapped to the related inbound ISignals of the COM component.
      RP_CAN_RT_8e1022: required-interface=if8e1022  # This is a required port for all signals of inbound CAN frame RT_SB_INS_Vel_NED_1, 9310242 (0x8e1022). The data elements of this port will typically be mapped to the related inbound ISignals of the COM component.
      RP_CAN_RT_8e0522: required-interface=if8e0522  # This is a required port for all signals of inbound CAN frame RT_SB_INS_Pos_ECEF_2, 9307426 (0x8e0522). The data elements of this port will typically be mapped to the related inbound ISignals of the COM component.
      RP_CAN_RT_8e0422: required-interface=if8e0422  # This is a required port for all signals of inbound CAN frame RT_SB_INS_Pos_ECEF_1, 9307170 (0x8e0422). The data elements of this port will typically be mapped to the related inbound ISignals of the COM component.
      RP_CAN_RT_8e0322: required-interface=if8e0322  # This is a required port for all signals of inbound CAN frame RT_SB_INS_Pos_LLH_2, 9306914 (0x8e0322). The data elements of this port will typically be mapped to the related inbound ISignals of the COM component.
      RP_CAN_RT_8e0222: required-interface=if8e0222  # This is a required port for all signals of inbound CAN frame RT_SB_INS_Pos_LLH_1, 9306658 (0x8e0222). The data elements of this port will typically be mapped to the related inbound ISignals of the COM component.
      RP_CAN_RT_8e1522: required-interface=if8e1522  # This is a required port for all signals of inbound CAN frame RT_SB_INS_Heading_Gradient_2, 9311522 (0x8e1522). The data elements of this port will typically be mapped to the related inbound ISignals of the COM component.
      RP_CAN_RT_8e1422: required-interface=if8e1422  # This is a required port for all signals of inbound CAN frame RT_SB_INS_Heading_Gradient, 9311266 (0x8e1422). The data elements of this port will typically be mapped to the related inbound ISignals of the COM component.
      RP_CAN_RT_8e0022: required-interface=if8e0022  # This is a required port for all signals of inbound CAN frame RT_SB_INS_Status, 9306146 (0x8e0022). The data elements of this port will typically be mapped to the related inbound ISignals of the COM component.
      RP_CAN_RT_8e0122: required-interface=if8e0122  # This is a required port for all signals of inbound CAN frame RT_SB_INS_Attitude, 9306402 (0x8e0122). The data elements of this port will typically be mapped to the related inbound ISignals of the COM component.
      RP_CAN_RT_8d0122: required-interface=if8d0122  # This is a required port for all signals of inbound CAN frame RT_SB_Output_Status, 9240866 (0x8d0122). The data elements of this port will typically be mapped to the related inbound ISignals of the COM component.
      RP_CAN_RT_8c1622: required-interface=if8c1622  # This is a required port for all signals of inbound CAN frame RT_SB_GPS_Heading_Gradient_2, 9180706 (0x8c1622). The data elements of this port will typically be mapped to the related inbound ISignals of the COM component.
      RP_CAN_RT_802122: required-interface=if802122  # This is a required port for all signals of inbound CAN frame RT_SB_Cumulative_Distance_2, 8397090 (0x802122). The data elements of this port will typically be mapped to the related inbound ISignals of the COM component. This cumulative distance calculation is updated when the trigger is active.
      RP_CAN_RT_802022: required-interface=if802022  # This is a required port for all signals of inbound CAN frame RT_SB_Cumulative_Distance_1, 8396834 (0x802022). The data elements of this port will typically be mapped to the related inbound ISignals of the COM component. This cumulative distance calculation is updated continuously once the first good GPS lock is obtained.
      RP_CAN_RT_8d0022: required-interface=if8d0022  # This is a required port for all signals of inbound CAN frame RT_SB_Trigger_Timestamp, 9240610 (0x8d0022). The data elements of this port will typically be mapped to the related inbound ISignals of the COM component.
      RP_CAN_RT_800121: required-interface=if800121  # This is a required port for all signals of inbound CAN frame RT_IMU06_Gyro_Rates, 8388897 (0x800121). The data elements of this port will typically be mapped to the related inbound ISignals of the COM component.
      RP_CAN_RT_800021: required-interface=if800021  # This is a required port for all signals of inbound CAN frame RT_IMU06_Accel, 8388641 (0x800021). The data elements of this port will typically be mapped to the related inbound ISignals of the COM component.
      RP_CAN_RT_801022: required-interface=if801022  # This is a required port for all signals of inbound CAN frame RT_SB_Speed, 8392738 (0x801022). The data elements of this port will typically be mapped to the related inbound ISignals of the COM component.
      RP_CAN_RT_8c2122: required-interface=if8c2122  # This is a required port for all signals of inbound CAN frame RT_SB_RTK_Slip, 9183522 (0x8c2122). The data elements of this port will typically be mapped to the related inbound ISignals of the COM component.
      RP_CAN_RT_8c2022: required-interface=if8c2022  # This is a required port for all signals of inbound CAN frame RT_SB_RTK_Attitude, 9183266 (0x8c2022). The data elements of this port will typically be mapped to the related inbound ISignals of the COM component.
      RP_CAN_RT_8c3022: required-interface=if8c3022  # This is a required port for all signals of inbound CAN frame RT_SB_GPS_Mcycle_Lean, 9187362 (0x8c3022). The data elements of this port will typically be mapped to the related inbound ISignals of the COM component.
      RP_CAN_RT_8c0022: required-interface=if8c0022  # This is a required port for all signals of inbound CAN frame RT_SB_GPS_Status, 9175074 (0x8c0022). The data elements of this port will typically be mapped to the related inbound ISignals of the COM component.
      RP_CAN_RT_8c0522: required-interface=if8c0522  # This is a required port for all signals of inbound CAN frame RT_SB_GPS_Pos_ECEF_2, 9176354 (0x8c0522). The data elements of this port will typically be mapped to the related inbound ISignals of the COM component.
      RP_CAN_RT_8c0422: required-interface=if8c0422  # This is a required port for all signals of inbound CAN frame RT_SB_GPS_Pos_ECEF_1, 9176098 (0x8c0422). The data elements of this port will typically be mapped to the related inbound ISignals of the COM component.
      RP_CAN_RT_8c0322: required-interface=if8c0322  # This is a required port for all signals of inbound CAN frame RT_SB_GPS_Pos_LLH_2, 9175842 (0x8c0322). The data elements of this port will typically be mapped to the related inbound ISignals of the COM component.
      RP_CAN_RT_8c0222: required-interface=if8c0222  # This is a required port for all signals of inbound CAN frame RT_SB_GPS_Pos_LLH_1, 9175586 (0x8c0222). The data elements of this port will typically be mapped to the related inbound ISignals of the COM component.
      RP_CAN_RT_8c1522: required-interface=if8c1522  # This is a required port for all signals of inbound CAN frame RT_SB_GPS_Heading_Gradient, 9180450 (0x8c1522). The data elements of this port will typically be mapped to the related inbound ISignals of the COM component.
      RP_CAN_RT_8c1422: required-interface=if8c1422  # This is a required port for all signals of inbound CAN frame RT_SB_GPS_Vel_ECEF_2, 9180194 (0x8c1422). The data elements of this port will typically be mapped to the related inbound ISignals of the COM component.
      RP_CAN_RT_8c1322: required-interface=if8c1322  # This is a required port for all signals of inbound CAN frame RT_SB_GPS_Vel_ECEF_1, 9179938 (0x8c1322). The data elements of this port will typically be mapped to the related inbound ISignals of the COM component.
      RP_CAN_RT_000: required-interface=if000  # This is a required port for all signals of inbound CAN frame RT_SB_GPS_Vel_NED_2, 0 (0x000). The data elements of this port will typically be mapped to the related inbound ISignals of the COM component.
      RP_CAN_RT_1fffffff: required-interface=if1fffffff  # This is a required port for all signals of inbound CAN frame RT_SB_GPS_Vel_NED_1, 536870911 (0x1fffffff). The data elements of this port will typically be mapped to the related inbound ISignals of the COM component.
      RP_CAN_RT_71a: required-interface=if71a  # This is a required port for all signals of inbound CAN frame RT_SB_GPS_Speed, 1818 (0x71a). The data elements of this port will typically be mapped to the related inbound ISignals of the COM component.
      RP_CAN_RT_7ff: required-interface=if7ff  # This is a required port for all signals of inbound CAN frame RT_SB_GPS_Time, 2047 (0x7ff). The data elements of this port will typically be mapped to the related inbound ISignals of the COM component.
      RP_CAN_RT_122: required-interface=if122  # This is a required port for all signals of inbound CAN frame RT_SB_Accel, 290 (0x122). The data elements of this port will typically be mapped to the related inbound ISignals of the COM component.
      RP_CAN_RT_800122: required-interface=if800122  # This is a required port for all signals of inbound CAN frame RT_SB_Gyro_Rates, 8388898 (0x800122). The data elements of this port will typically be mapped to the related inbound ISignals of the COM component.
    behavior ib_cif_swcCanInterface: data-type-mapping=cif_dataTypeMappingSet, handle-termination-and-restart=NO-SUPPORT  # The internal behavior of SW-C cif_swcCanInterface that implements the CAN interface of the APSW of the AUTOSAR application. It has by default a single runnable, which has access to all in- and outbound CAN signals by sender/receiver ports. The implementation of the SW-C can process all CAN signals and/or delegate them to other SW-Cs. The intention is to connect all the ports' data elements to the related ISignals of the COM component in the BSW
      timing event eventRegular: start-on-event=reApswCanInterface, period=0.01  # This event is just an example of how the SW-C and its runnable could be integrated into a real environment. If done by a regular timer event as this one, one would process all CAN signals in a regular timing pattern, which actually means a kind of polling. Real application will need a more sophisticated approach, at least several such runnables at different update rates
      runnable reApswCanInterface: symbol=cif_reApswCanInterface  # This runnable is configured to have read access to all signals of all inbound CAN frames of all buses and it has write access to all signals of all outbound frames of all buses. It is triggered periodically by a regular event
        data-receive-point-by-arguments:
          451 x access:
            DRP_RP_CAN_RT_0d7_Validity_INS_Vel_Forwards: accessed-variable=RP_CAN_RT_0d7.Validity_INS_Vel_Forwards  # Grant read access to input signal Validity_INS_Vel_Forwards to the runnable
            DRP_RP_CAN_RT_0d7_Validity_INS_Vel_Sideways: accessed-variable=RP_CAN_RT_0d7.Validity_INS_Vel_Sideways  # Grant read access to input signal Validity_INS_Vel_Sideways to the runnable
            DRP_RP_CAN_RT_0d7_Bit4: accessed-variable=RP_CAN_RT_0d7.Bit4  # Grant read access to input signal Bit4 to the runnable
            DRP_RP_CAN_RT_0d7_Bit7: accessed-variable=RP_CAN_RT_0d7.Bit7  # Grant read access to input signal Bit7 to the runnable
            DRP_RP_CAN_RT_0d7_Byte2_Bit0: accessed-variable=RP_CAN_RT_0d7.Byte2_Bit0  # Grant read access to input signal Byte2_Bit0 to the runnable
            DRP_RP_CAN_RT_0d7_INS_Vel_Sideways_2D: accessed-variable=RP_CAN_RT_0d7.INS_Vel_Sideways_2D  # Grant read access to input signal INS_Vel_Sideways_2D to the runnable
            DRP_RP_CAN_RT_0d7_Byte4_Bits67: accessed-variable=RP_CAN_RT_0d7.Byte4_Bits67  # Grant read access to input signal Byte4_Bits67 to the runnable
            DRP_RP_CAN_RT_0d7_Accuracy_INS_Vel_Body_org: accessed-variable=RP_CAN_RT_0d7.Accuracy_INS_Vel_Body_org  # Grant read access to input signal Accuracy_INS_Vel_Body_org to the runnable
            DRP_RP_CAN_RT_0d7_INS_Vel_Forwards_2D_org: accessed-variable=RP_CAN_RT_0d7.INS_Vel_Forwards_2D_org  # Grant read access to input signal INS_Vel_Forwards_2D_org to the runnable
            DRP_RP_CAN_RT_0d7_Accuracy_INS_Vel_Body_no2: accessed-variable=RP_CAN_RT_0d7.Accuracy_INS_Vel_Body_no2  # Grant read access to input signal Accuracy_INS_Vel_Body_no2 to the runnable
            DRP_RP_CAN_RT_0d7_INS_Vel_Forwards_2D_no2: accessed-variable=RP_CAN_RT_0d7.INS_Vel_Forwards_2D_no2  # Grant read access to input signal INS_Vel_Forwards_2D_no2 to the runnable
            DRP_RP_CAN_RT_0d7_Accuracy_INS_Vel_Body_no3: accessed-variable=RP_CAN_RT_0d7.Accuracy_INS_Vel_Body_no3  # Grant read access to input signal Accuracy_INS_Vel_Body_no3 to the runnable
            DRP_RP_CAN_RT_0d7_INS_Vel_Forwards_2D_no3: accessed-variable=RP_CAN_RT_0d7.INS_Vel_Forwards_2D_no3  # Grant read access to input signal INS_Vel_Forwards_2D_no3 to the runnable
            DRP_RP_CAN_RT_801024_Validity_Speed: accessed-variable=RP_CAN_RT_801024.Validity_Speed  # Grant read access to input signal Validity_Speed to the runnable
            DRP_RP_CAN_RT_801024_Accuracy_Speed: accessed-variable=RP_CAN_RT_801024.Accuracy_Speed  # Grant read access to input signal Accuracy_Speed to the runnable
            DRP_RP_CAN_RT_801024_Direction: accessed-variable=RP_CAN_RT_801024.Direction  # Grant read access to input signal Direction to the runnable
            DRP_RP_CAN_RT_801024_Speed: accessed-variable=RP_CAN_RT_801024.Speed  # Grant read access to input signal Speed to the runnable
            DRP_RP_CAN_RT_8c0124_Validity_GPS_Time: accessed-variable=RP_CAN_RT_8c0124.Validity_GPS_Time  # Grant read access to input signal Validity_GPS_Time to the runnable
            DRP_RP_CAN_RT_8c0124_Validity_GPS_Week: accessed-variable=RP_CAN_RT_8c0124.Validity_GPS_Week  # Grant read access to input signal Validity_GPS_Week to the runnable
            DRP_RP_CAN_RT_8c0124_Accuracy_GPS_Time: accessed-variable=RP_CAN_RT_8c0124.Accuracy_GPS_Time  # Grant read access to input signal Accuracy_GPS_Time to the runnable
            DRP_RP_CAN_RT_8c0124_GPS_Time: accessed-variable=RP_CAN_RT_8c0124.GPS_Time  # Grant read access to input signal GPS_Time to the runnable
            DRP_RP_CAN_RT_8c0124_GPS_Week: accessed-variable=RP_CAN_RT_8c0124.GPS_Week  # Grant read access to input signal GPS_Week to the runnable
            DRP_RP_CAN_RT_8c0324_GPS_Pos_LLH_Longitude: accessed-variable=RP_CAN_RT_8c0324.GPS_Pos_LLH_Longitude  # Grant read access to input signal GPS_Pos_LLH_Longitude to the runnable
            DRP_RP_CAN_RT_8c0324_GPS_Pos_LLH_Altitude: accessed-variable=RP_CAN_RT_8c0324.GPS_Pos_LLH_Altitude  # Grant read access to input signal GPS_Pos_LLH_Altitude to the runnable
            DRP_RP_CAN_RT_8c0224_Validity_GPS_Pos_LLH_Latitude: accessed-variable=RP_CAN_RT_8c0224.Validity_GPS_Pos_LLH_Latitude  # Grant read access to input signal Validity_GPS_Pos_LLH_Latitude to the runnable
            DRP_RP_CAN_RT_8c0224_Validity_GPS_Pos_LLH_Longitude: accessed-variable=RP_CAN_RT_8c0224.Validity_GPS_Pos_LLH_Longitude  # Grant read access to input signal Validity_GPS_Pos_LLH_Longitude to the runnable
            DRP_RP_CAN_RT_8c0224_Validity_GPS_Pos_LLH_Altitude: accessed-variable=RP_CAN_RT_8c0224.Validity_GPS_Pos_LLH_Altitude  # Grant read access to input signal Validity_GPS_Pos_LLH_Altitude to the runnable
            DRP_RP_CAN_RT_8c0224_Accuracy_GPS_Pos_LLH_Latitude: accessed-variable=RP_CAN_RT_8c0224.Accuracy_GPS_Pos_LLH_Latitude  # Grant read access to input signal Accuracy_GPS_Pos_LLH_Latitude to the runnable
            DRP_RP_CAN_RT_8c0224_Accuracy_GPS_Pos_LLH_Longitude: accessed-variable=RP_CAN_RT_8c0224.Accuracy_GPS_Pos_LLH_Longitude  # Grant read access to input signal Accuracy_GPS_Pos_LLH_Longitude to the runnable
            DRP_RP_CAN_RT_8c0224_Accuracy_GPS_Pos_LLH_Altitude: accessed-variable=RP_CAN_RT_8c0224.Accuracy_GPS_Pos_LLH_Altitude  # Grant read access to input signal Accuracy_GPS_Pos_LLH_Altitude to the runnable
            DRP_RP_CAN_RT_8c0224_GPS_Pos_LLH_Latitude: accessed-variable=RP_CAN_RT_8c0224.GPS_Pos_LLH_Latitude  # Grant read access to input signal GPS_Pos_LLH_Latitude to the runnable
            DRP_RP_CAN_RT_4d2_Validity_GPS_Speed_2D: accessed-variable=RP_CAN_RT_4d2.Validity_GPS_Speed_2D  # Grant read access to input signal Validity_GPS_Speed_2D to the runnable
            DRP_RP_CAN_RT_4d2_Validity_GPS_Speed_3D: accessed-variable=RP_CAN_RT_4d2.Validity_GPS_Speed_3D  # Grant read access to input signal Validity_GPS_Speed_3D to the runnable
            DRP_RP_CAN_RT_4d2_Accuracy_GPS_Speed: accessed-variable=RP_CAN_RT_4d2.Accuracy_GPS_Speed  # Grant read access to input signal Accuracy_GPS_Speed to the runnable
            DRP_RP_CAN_RT_4d2_GPS_Speed_2D: accessed-variable=RP_CAN_RT_4d2.GPS_Speed_2D  # Grant read access to input signal GPS_Speed_2D to the runnable
            DRP_RP_CAN_RT_4d2_GPS_Speed_3D: accessed-variable=RP_CAN_RT_4d2.GPS_Speed_3D  # Grant read access to input signal GPS_Speed_3D to the runnable
            DRP_RP_CAN_RT_980825_IR_Temperature_{29..32}: accessed-variable=RP_CAN_RT_980825.IR_Temperature_{29..32}  # Grant read access to input signal IR_Temperature_{29..32} to the runnable
            DRP_RP_CAN_RT_980225_IR_Temperature_{5..8}: accessed-variable=RP_CAN_RT_980225.IR_Temperature_{5..8}  # Grant read access to input signal IR_Temperature_{5..8} to the runnable
            DRP_RP_CAN_RT_980725_IR_Temperature_{25..28}: accessed-variable=RP_CAN_RT_980725.IR_Temperature_{25..28}  # Grant read access to input signal IR_Temperature_{25..28} to the runnable
            DRP_RP_CAN_RT_980525_IR_Temperature_{17..20}: accessed-variable=RP_CAN_RT_980525.IR_Temperature_{17..20}  # Grant read access to input signal IR_Temperature_{17..20} to the runnable
            DRP_RP_CAN_RT_980325_IR_Temperature_{9..12}: accessed-variable=RP_CAN_RT_980325.IR_Temperature_{9..12}  # Grant read access to input signal IR_Temperature_{9..12} to the runnable
            DRP_RP_CAN_RT_980125_IR_Temperature_{1..4}: accessed-variable=RP_CAN_RT_980125.IR_Temperature_{1..4}  # Grant read access to input signal IR_Temperature_{1..4} to the runnable
            DRP_RP_CAN_RT_912025_IR_Temperature_32: accessed-variable=RP_CAN_RT_912025.IR_Temperature_32  # Grant read access to input signal IR_Temperature_32 to the runnable
            DRP_RP_CAN_RT_911f25_IR_Temperature_31: accessed-variable=RP_CAN_RT_911f25.IR_Temperature_31  # Grant read access to input signal IR_Temperature_31 to the runnable
            DRP_RP_CAN_RT_911d25_IR_Temperature_29: accessed-variable=RP_CAN_RT_911d25.IR_Temperature_29  # Grant read access to input signal IR_Temperature_29 to the runnable
            DRP_RP_CAN_RT_911c25_IR_Temperature_28: accessed-variable=RP_CAN_RT_911c25.IR_Temperature_28  # Grant read access to input signal IR_Temperature_28 to the runnable
            DRP_RP_CAN_RT_911b25_IR_Temperature_27: accessed-variable=RP_CAN_RT_911b25.IR_Temperature_27  # Grant read access to input signal IR_Temperature_27 to the runnable
            DRP_RP_CAN_RT_911925_IR_Temperature_25: accessed-variable=RP_CAN_RT_911925.IR_Temperature_25  # Grant read access to input signal IR_Temperature_25 to the runnable
            DRP_RP_CAN_RT_911825_IR_Temperature_24: accessed-variable=RP_CAN_RT_911825.IR_Temperature_24  # Grant read access to input signal IR_Temperature_24 to the runnable
            DRP_RP_CAN_RT_911625_IR_Temperature_22: accessed-variable=RP_CAN_RT_911625.IR_Temperature_22  # Grant read access to input signal IR_Temperature_22 to the runnable
            DRP_RP_CAN_RT_911725_IR_Temperature_23: accessed-variable=RP_CAN_RT_911725.IR_Temperature_23  # Grant read access to input signal IR_Temperature_23 to the runnable
            DRP_RP_CAN_RT_911525_IR_Temperature_21: accessed-variable=RP_CAN_RT_911525.IR_Temperature_21  # Grant read access to input signal IR_Temperature_21 to the runnable
            DRP_RP_CAN_RT_911425_IR_Temperature_20: accessed-variable=RP_CAN_RT_911425.IR_Temperature_20  # Grant read access to input signal IR_Temperature_20 to the runnable
            DRP_RP_CAN_RT_911325_IR_Temperature_19: accessed-variable=RP_CAN_RT_911325.IR_Temperature_19  # Grant read access to input signal IR_Temperature_19 to the runnable
            DRP_RP_CAN_RT_911225_IR_Temperature_18: accessed-variable=RP_CAN_RT_911225.IR_Temperature_18  # Grant read access to input signal IR_Temperature_18 to the runnable
            DRP_RP_CAN_RT_911025_IR_Temperature_16: accessed-variable=RP_CAN_RT_911025.IR_Temperature_16  # Grant read access to input signal IR_Temperature_16 to the runnable
            DRP_RP_CAN_RT_910f25_IR_Temperature_15: accessed-variable=RP_CAN_RT_910f25.IR_Temperature_15  # Grant read access to input signal IR_Temperature_15 to the runnable
            DRP_RP_CAN_RT_910e25_IR_Temperature_14: accessed-variable=RP_CAN_RT_910e25.IR_Temperature_14  # Grant read access to input signal IR_Temperature_14 to the runnable
            DRP_RP_CAN_RT_910d25_IR_Temperature_13: accessed-variable=RP_CAN_RT_910d25.IR_Temperature_13  # Grant read access to input signal IR_Temperature_13 to the runnable
            DRP_RP_CAN_RT_910c25_IR_Temperature_12: accessed-variable=RP_CAN_RT_910c25.IR_Temperature_12  # Grant read access to input signal IR_Temperature_12 to the runnable
            DRP_RP_CAN_RT_910b25_IR_Temperature_11: accessed-variable=RP_CAN_RT_910b25.IR_Temperature_11  # Grant read access to input signal IR_Temperature_11 to the runnable
            DRP_RP_CAN_RT_910a25_IR_Temperature_10: accessed-variable=RP_CAN_RT_910a25.IR_Temperature_10  # Grant read access to input signal IR_Temperature_10 to the runnable
            DRP_RP_CAN_RT_910825_IR_Temperature_8: accessed-variable=RP_CAN_RT_910825.IR_Temperature_8  # Grant read access to input signal IR_Temperature_8 to the runnable
            DRP_RP_CAN_RT_910925_IR_Temperature_9: accessed-variable=RP_CAN_RT_910925.IR_Temperature_9  # Grant read access to input signal IR_Temperature_9 to the runnable
            DRP_RP_CAN_RT_911125_IR_Temperature_17: accessed-variable=RP_CAN_RT_911125.IR_Temperature_17  # Grant read access to input signal IR_Temperature_17 to the runnable
            DRP_RP_CAN_RT_910625_IR_Temperature_6: accessed-variable=RP_CAN_RT_910625.IR_Temperature_6  # Grant read access to input signal IR_Temperature_6 to the runnable
            DRP_RP_CAN_RT_910525_IR_Temperature_5: accessed-variable=RP_CAN_RT_910525.IR_Temperature_5  # Grant read access to input signal IR_Temperature_5 to the runnable
            DRP_RP_CAN_RT_910425_IR_Temperature_4: accessed-variable=RP_CAN_RT_910425.IR_Temperature_4  # Grant read access to input signal IR_Temperature_4 to the runnable
            DRP_RP_CAN_RT_910325_IR_Temperature_3: accessed-variable=RP_CAN_RT_910325.IR_Temperature_3  # Grant read access to input signal IR_Temperature_3 to the runnable
            DRP_RP_CAN_RT_910225_IR_Temperature_2: accessed-variable=RP_CAN_RT_910225.IR_Temperature_2  # Grant read access to input signal IR_Temperature_2 to the runnable
            DRP_RP_CAN_RT_910125_IR_Temperature_1: accessed-variable=RP_CAN_RT_910125.IR_Temperature_1  # Grant read access to input signal IR_Temperature_1 to the runnable
            DRP_RP_CAN_RT_8d0722_Validity_Final_Speed: accessed-variable=RP_CAN_RT_8d0722.Validity_Final_Speed  # Grant read access to input signal Validity_Final_Speed to the runnable
            DRP_RP_CAN_RT_8d0722_Final_Speed: accessed-variable=RP_CAN_RT_8d0722.Final_Speed  # Grant read access to input signal Final_Speed to the runnable
            DRP_RP_CAN_RT_31a_Validity_Initial_Speed: accessed-variable=RP_CAN_RT_31a.Validity_Initial_Speed  # Grant read access to input signal Validity_Initial_Speed to the runnable
            DRP_RP_CAN_RT_31a_Validity_Initial_Heading: accessed-variable=RP_CAN_RT_31a.Validity_Initial_Heading  # Grant read access to input signal Validity_Initial_Heading to the runnable
            DRP_RP_CAN_RT_31a_Initial_Speed: accessed-variable=RP_CAN_RT_31a.Initial_Speed  # Grant read access to input signal Initial_Speed to the runnable
            DRP_RP_CAN_RT_31a_Initial_Heading: accessed-variable=RP_CAN_RT_31a.Initial_Heading  # Grant read access to input signal Initial_Heading to the runnable
            DRP_RP_CAN_RT_31a_MFDD_Start_Threshold: accessed-variable=RP_CAN_RT_31a.MFDD_Start_Threshold  # Grant read access to input signal MFDD_Start_Threshold to the runnable
            DRP_RP_CAN_RT_31a_MFDD_End_Threshold: accessed-variable=RP_CAN_RT_31a.MFDD_End_Threshold  # Grant read access to input signal MFDD_End_Threshold to the runnable
            DRP_RP_CAN_RT_8d0522_Direct_Distance: accessed-variable=RP_CAN_RT_8d0522.Direct_Distance  # Grant read access to input signal Direct_Distance to the runnable
            DRP_RP_CAN_RT_8d0522_Path_Distance_2D: accessed-variable=RP_CAN_RT_8d0522.Path_Distance_2D  # Grant read access to input signal Path_Distance_2D to the runnable
            DRP_RP_CAN_RT_8d0322_Path_Distance_3D: accessed-variable=RP_CAN_RT_8d0322.Path_Distance_3D  # Grant read access to input signal Path_Distance_3D to the runnable
            DRP_RP_CAN_RT_960b24_Measured_Time_11: accessed-variable=RP_CAN_RT_960b24.Measured_Time_11  # Grant read access to input signal Measured_Time_11 to the runnable
            DRP_RP_CAN_RT_960a24_Measured_Time_10: accessed-variable=RP_CAN_RT_960a24.Measured_Time_10  # Grant read access to input signal Measured_Time_10 to the runnable
            DRP_RP_CAN_RT_960924_Measured_Time_9: accessed-variable=RP_CAN_RT_960924.Measured_Time_9  # Grant read access to input signal Measured_Time_9 to the runnable
            DRP_RP_CAN_RT_960824_Measured_Time_8: accessed-variable=RP_CAN_RT_960824.Measured_Time_8  # Grant read access to input signal Measured_Time_8 to the runnable
            DRP_RP_CAN_RT_960724_Measured_Time_7: accessed-variable=RP_CAN_RT_960724.Measured_Time_7  # Grant read access to input signal Measured_Time_7 to the runnable
            DRP_RP_CAN_RT_960624_Measured_Time_6: accessed-variable=RP_CAN_RT_960624.Measured_Time_6  # Grant read access to input signal Measured_Time_6 to the runnable
            DRP_RP_CAN_RT_960524_Measured_Time_5: accessed-variable=RP_CAN_RT_960524.Measured_Time_5  # Grant read access to input signal Measured_Time_5 to the runnable
            DRP_RP_CAN_RT_960424_Measured_Time_4: accessed-variable=RP_CAN_RT_960424.Measured_Time_4  # Grant read access to input signal Measured_Time_4 to the runnable
            DRP_RP_CAN_RT_960324_Measured_Time_3: accessed-variable=RP_CAN_RT_960324.Measured_Time_3  # Grant read access to input signal Measured_Time_3 to the runnable
            DRP_RP_CAN_RT_960224_Measured_Time_2: accessed-variable=RP_CAN_RT_960224.Measured_Time_2  # Grant read access to input signal Measured_Time_2 to the runnable
            DRP_RP_CAN_RT_960124_Measured_Time_1: accessed-variable=RP_CAN_RT_960124.Measured_Time_1  # Grant read access to input signal Measured_Time_1 to the runnable
            DRP_RP_CAN_RT_950c24_RPM: accessed-variable=RP_CAN_RT_950c24.RPM  # Grant read access to input signal RPM to the runnable
            DRP_RP_CAN_RT_950b24_Frequency_4: accessed-variable=RP_CAN_RT_950b24.Frequency_4  # Grant read access to input signal Frequency_4 to the runnable
            DRP_RP_CAN_RT_950a24_Frequency_3: accessed-variable=RP_CAN_RT_950a24.Frequency_3  # Grant read access to input signal Frequency_3 to the runnable
            DRP_RP_CAN_RT_950924_Frequency_2: accessed-variable=RP_CAN_RT_950924.Frequency_2  # Grant read access to input signal Frequency_2 to the runnable
            DRP_RP_CAN_RT_970324_Misc_3: accessed-variable=RP_CAN_RT_970324.Misc_3  # Grant read access to input signal Misc_3 to the runnable
            DRP_RP_CAN_RT_970224_Misc_2: accessed-variable=RP_CAN_RT_970224.Misc_2  # Grant read access to input signal Misc_2 to the runnable
            DRP_RP_CAN_RT_970124_Misc_1: accessed-variable=RP_CAN_RT_970124.Misc_1  # Grant read access to input signal Misc_1 to the runnable
            DRP_RP_CAN_RT_941f24_AUX_31: accessed-variable=RP_CAN_RT_941f24.AUX_31  # Grant read access to input signal AUX_31 to the runnable
            DRP_RP_CAN_RT_941e24_AUX_30: accessed-variable=RP_CAN_RT_941e24.AUX_30  # Grant read access to input signal AUX_30 to the runnable
            DRP_RP_CAN_RT_941d24_AUX_29: accessed-variable=RP_CAN_RT_941d24.AUX_29  # Grant read access to input signal AUX_29 to the runnable
            DRP_RP_CAN_RT_941c24_AUX_28: accessed-variable=RP_CAN_RT_941c24.AUX_28  # Grant read access to input signal AUX_28 to the runnable
            DRP_RP_CAN_RT_941b24_AUX_27: accessed-variable=RP_CAN_RT_941b24.AUX_27  # Grant read access to input signal AUX_27 to the runnable
            DRP_RP_CAN_RT_941a24_AUX_26: accessed-variable=RP_CAN_RT_941a24.AUX_26  # Grant read access to input signal AUX_26 to the runnable
            DRP_RP_CAN_RT_941924_AUX_25: accessed-variable=RP_CAN_RT_941924.AUX_25  # Grant read access to input signal AUX_25 to the runnable
            DRP_RP_CAN_RT_941824_AUX_24: accessed-variable=RP_CAN_RT_941824.AUX_24  # Grant read access to input signal AUX_24 to the runnable
            DRP_RP_CAN_RT_941724_AUX_23: accessed-variable=RP_CAN_RT_941724.AUX_23  # Grant read access to input signal AUX_23 to the runnable
            DRP_RP_CAN_RT_941624_AUX_22: accessed-variable=RP_CAN_RT_941624.AUX_22  # Grant read access to input signal AUX_22 to the runnable
            DRP_RP_CAN_RT_941524_AUX_21: accessed-variable=RP_CAN_RT_941524.AUX_21  # Grant read access to input signal AUX_21 to the runnable
            DRP_RP_CAN_RT_941424_AUX_20: accessed-variable=RP_CAN_RT_941424.AUX_20  # Grant read access to input signal AUX_20 to the runnable
            DRP_RP_CAN_RT_941324_AUX_19: accessed-variable=RP_CAN_RT_941324.AUX_19  # Grant read access to input signal AUX_19 to the runnable
            DRP_RP_CAN_RT_941224_AUX_18: accessed-variable=RP_CAN_RT_941224.AUX_18  # Grant read access to input signal AUX_18 to the runnable
            DRP_RP_CAN_RT_941124_AUX_17: accessed-variable=RP_CAN_RT_941124.AUX_17  # Grant read access to input signal AUX_17 to the runnable
            DRP_RP_CAN_RT_941024_AUX_16: accessed-variable=RP_CAN_RT_941024.AUX_16  # Grant read access to input signal AUX_16 to the runnable
            DRP_RP_CAN_RT_940f24_AUX_15: accessed-variable=RP_CAN_RT_940f24.AUX_15  # Grant read access to input signal AUX_15 to the runnable
            DRP_RP_CAN_RT_940e24_AUX_14: accessed-variable=RP_CAN_RT_940e24.AUX_14  # Grant read access to input signal AUX_14 to the runnable
            DRP_RP_CAN_RT_940d24_AUX_13: accessed-variable=RP_CAN_RT_940d24.AUX_13  # Grant read access to input signal AUX_13 to the runnable
            DRP_RP_CAN_RT_940c24_AUX_12: accessed-variable=RP_CAN_RT_940c24.AUX_12  # Grant read access to input signal AUX_12 to the runnable
            DRP_RP_CAN_RT_940b24_AUX_11: accessed-variable=RP_CAN_RT_940b24.AUX_11  # Grant read access to input signal AUX_11 to the runnable
            DRP_RP_CAN_RT_940924_AUX_9: accessed-variable=RP_CAN_RT_940924.AUX_9  # Grant read access to input signal AUX_9 to the runnable
            DRP_RP_CAN_RT_940a24_AUX_10: accessed-variable=RP_CAN_RT_940a24.AUX_10  # Grant read access to input signal AUX_10 to the runnable
            DRP_RP_CAN_RT_940824_AUX_8: accessed-variable=RP_CAN_RT_940824.AUX_8  # Grant read access to input signal AUX_8 to the runnable
            DRP_RP_CAN_RT_940724_AUX_7: accessed-variable=RP_CAN_RT_940724.AUX_7  # Grant read access to input signal AUX_7 to the runnable
            DRP_RP_CAN_RT_940624_AUX_6: accessed-variable=RP_CAN_RT_940624.AUX_6  # Grant read access to input signal AUX_6 to the runnable
            DRP_RP_CAN_RT_940524_AUX_5: accessed-variable=RP_CAN_RT_940524.AUX_5  # Grant read access to input signal AUX_5 to the runnable
            DRP_RP_CAN_RT_940424_AUX_4: accessed-variable=RP_CAN_RT_940424.AUX_4  # Grant read access to input signal AUX_4 to the runnable
            DRP_RP_CAN_RT_940324_AUX_3: accessed-variable=RP_CAN_RT_940324.AUX_3  # Grant read access to input signal AUX_3 to the runnable
            DRP_RP_CAN_RT_940224_AUX_2: accessed-variable=RP_CAN_RT_940224.AUX_2  # Grant read access to input signal AUX_2 to the runnable
            DRP_RP_CAN_RT_940124_AUX_1: accessed-variable=RP_CAN_RT_940124.AUX_1  # Grant read access to input signal AUX_1 to the runnable
            DRP_RP_CAN_RT_900524_Pressure_5: accessed-variable=RP_CAN_RT_900524.Pressure_5  # Grant read access to input signal Pressure_5 to the runnable
            DRP_RP_CAN_RT_900424_Pressure_4: accessed-variable=RP_CAN_RT_900424.Pressure_4  # Grant read access to input signal Pressure_4 to the runnable
            DRP_RP_CAN_RT_900324_Pressure_3: accessed-variable=RP_CAN_RT_900324.Pressure_3  # Grant read access to input signal Pressure_3 to the runnable
            DRP_RP_CAN_RT_900224_Pressure_2: accessed-variable=RP_CAN_RT_900224.Pressure_2  # Grant read access to input signal Pressure_2 to the runnable
            DRP_RP_CAN_RT_900124_Pressure_1: accessed-variable=RP_CAN_RT_900124.Pressure_1  # Grant read access to input signal Pressure_1 to the runnable
            DRP_RP_CAN_RT_920324_Angle_3: accessed-variable=RP_CAN_RT_920324.Angle_3  # Grant read access to input signal Angle_3 to the runnable
            DRP_RP_CAN_RT_920224_Angle_2: accessed-variable=RP_CAN_RT_920224.Angle_2  # Grant read access to input signal Angle_2 to the runnable
            DRP_RP_CAN_RT_920124_Angle_1: accessed-variable=RP_CAN_RT_920124.Angle_1  # Grant read access to input signal Angle_1 to the runnable
            DRP_RP_CAN_RT_911924_Temperature_25: accessed-variable=RP_CAN_RT_911924.Temperature_25  # Grant read access to input signal Temperature_25 to the runnable
            DRP_RP_CAN_RT_911824_Temperature_24: accessed-variable=RP_CAN_RT_911824.Temperature_24  # Grant read access to input signal Temperature_24 to the runnable
            DRP_RP_CAN_RT_911724_Temperature_23: accessed-variable=RP_CAN_RT_911724.Temperature_23  # Grant read access to input signal Temperature_23 to the runnable
            DRP_RP_CAN_RT_911624_Temperature_22: accessed-variable=RP_CAN_RT_911624.Temperature_22  # Grant read access to input signal Temperature_22 to the runnable
            DRP_RP_CAN_RT_911524_Temperature_21: accessed-variable=RP_CAN_RT_911524.Temperature_21  # Grant read access to input signal Temperature_21 to the runnable
            DRP_RP_CAN_RT_911424_Temperature_20: accessed-variable=RP_CAN_RT_911424.Temperature_20  # Grant read access to input signal Temperature_20 to the runnable
            DRP_RP_CAN_RT_911324_Temperature_19: accessed-variable=RP_CAN_RT_911324.Temperature_19  # Grant read access to input signal Temperature_19 to the runnable
            DRP_RP_CAN_RT_911224_Temperature_18: accessed-variable=RP_CAN_RT_911224.Temperature_18  # Grant read access to input signal Temperature_18 to the runnable
            DRP_RP_CAN_RT_911124_Temperature_17: accessed-variable=RP_CAN_RT_911124.Temperature_17  # Grant read access to input signal Temperature_17 to the runnable
            DRP_RP_CAN_RT_911024_Temperature_16: accessed-variable=RP_CAN_RT_911024.Temperature_16  # Grant read access to input signal Temperature_16 to the runnable
            DRP_RP_CAN_RT_910f24_Temperature_15: accessed-variable=RP_CAN_RT_910f24.Temperature_15  # Grant read access to input signal Temperature_15 to the runnable
            DRP_RP_CAN_RT_910e24_Temperature_14: accessed-variable=RP_CAN_RT_910e24.Temperature_14  # Grant read access to input signal Temperature_14 to the runnable
            DRP_RP_CAN_RT_910d24_Temperature_13: accessed-variable=RP_CAN_RT_910d24.Temperature_13  # Grant read access to input signal Temperature_13 to the runnable
            DRP_RP_CAN_RT_910c24_Temperature_12: accessed-variable=RP_CAN_RT_910c24.Temperature_12  # Grant read access to input signal Temperature_12 to the runnable
            DRP_RP_CAN_RT_910b24_Temperature_11: accessed-variable=RP_CAN_RT_910b24.Temperature_11  # Grant read access to input signal Temperature_11 to the runnable
            DRP_RP_CAN_RT_910a24_Temperature_10: accessed-variable=RP_CAN_RT_910a24.Temperature_10  # Grant read access to input signal Temperature_10 to the runnable
            DRP_RP_CAN_RT_910924_Temperature_9: accessed-variable=RP_CAN_RT_910924.Temperature_9  # Grant read access to input signal Temperature_9 to the runnable
            DRP_RP_CAN_RT_910824_Temperature_8: accessed-variable=RP_CAN_RT_910824.Temperature_8  # Grant read access to input signal Temperature_8 to the runnable
            DRP_RP_CAN_RT_910724_Temperature_7: accessed-variable=RP_CAN_RT_910724.Temperature_7  # Grant read access to input signal Temperature_7 to the runnable
            DRP_RP_CAN_RT_910624_Temperature_6: accessed-variable=RP_CAN_RT_910624.Temperature_6  # Grant read access to input signal Temperature_6 to the runnable
            DRP_RP_CAN_RT_910524_Temperature_5: accessed-variable=RP_CAN_RT_910524.Temperature_5  # Grant read access to input signal Temperature_5 to the runnable
            DRP_RP_CAN_RT_910424_Temperature_4: accessed-variable=RP_CAN_RT_910424.Temperature_4  # Grant read access to input signal Temperature_4 to the runnable
            DRP_RP_CAN_RT_910324_Temperature_3: accessed-variable=RP_CAN_RT_910324.Temperature_3  # Grant read access to input signal Temperature_3 to the runnable
            DRP_RP_CAN_RT_910224_Temperature_2: accessed-variable=RP_CAN_RT_910224.Temperature_2  # Grant read access to input signal Temperature_2 to the runnable
            DRP_RP_CAN_RT_910124_Temperature_1: accessed-variable=RP_CAN_RT_910124.Temperature_1  # Grant read access to input signal Temperature_1 to the runnable
            DRP_RP_CAN_RT_821f24_Analog_32: accessed-variable=RP_CAN_RT_821f24.Analog_32  # Grant read access to input signal Analog_32 to the runnable
            DRP_RP_CAN_RT_821e24_Analog_31: accessed-variable=RP_CAN_RT_821e24.Analog_31  # Grant read access to input signal Analog_31 to the runnable
            DRP_RP_CAN_RT_821d24_Analog_30: accessed-variable=RP_CAN_RT_821d24.Analog_30  # Grant read access to input signal Analog_30 to the runnable
            DRP_RP_CAN_RT_821c24_Analog_29: accessed-variable=RP_CAN_RT_821c24.Analog_29  # Grant read access to input signal Analog_29 to the runnable
            DRP_RP_CAN_RT_821b24_Analog_28: accessed-variable=RP_CAN_RT_821b24.Analog_28  # Grant read access to input signal Analog_28 to the runnable
            DRP_RP_CAN_RT_821a24_Analog_27: accessed-variable=RP_CAN_RT_821a24.Analog_27  # Grant read access to input signal Analog_27 to the runnable
            DRP_RP_CAN_RT_821924_Analog_26: accessed-variable=RP_CAN_RT_821924.Analog_26  # Grant read access to input signal Analog_26 to the runnable
            DRP_RP_CAN_RT_821824_Analog_25: accessed-variable=RP_CAN_RT_821824.Analog_25  # Grant read access to input signal Analog_25 to the runnable
            DRP_RP_CAN_RT_820e24_Analog_15: accessed-variable=RP_CAN_RT_820e24.Analog_15  # Grant read access to input signal Analog_15 to the runnable
            DRP_RP_CAN_RT_820d24_Analog_14: accessed-variable=RP_CAN_RT_820d24.Analog_14  # Grant read access to input signal Analog_14 to the runnable
            DRP_RP_CAN_RT_821024_Analog_17: accessed-variable=RP_CAN_RT_821024.Analog_17  # Grant read access to input signal Analog_17 to the runnable
            DRP_RP_CAN_RT_821724_Analog_24: accessed-variable=RP_CAN_RT_821724.Analog_24  # Grant read access to input signal Analog_24 to the runnable
            DRP_RP_CAN_RT_821624_Analog_23: accessed-variable=RP_CAN_RT_821624.Analog_23  # Grant read access to input signal Analog_23 to the runnable
            DRP_RP_CAN_RT_821524_Analog_22: accessed-variable=RP_CAN_RT_821524.Analog_22  # Grant read access to input signal Analog_22 to the runnable
            DRP_RP_CAN_RT_821424_Analog_21: accessed-variable=RP_CAN_RT_821424.Analog_21  # Grant read access to input signal Analog_21 to the runnable
            DRP_RP_CAN_RT_821324_Analog_20: accessed-variable=RP_CAN_RT_821324.Analog_20  # Grant read access to input signal Analog_20 to the runnable
            DRP_RP_CAN_RT_821224_Analog_19: accessed-variable=RP_CAN_RT_821224.Analog_19  # Grant read access to input signal Analog_19 to the runnable
            DRP_RP_CAN_RT_820f24_Analog_16: accessed-variable=RP_CAN_RT_820f24.Analog_16  # Grant read access to input signal Analog_16 to the runnable
            DRP_RP_CAN_RT_821124_Analog_18: accessed-variable=RP_CAN_RT_821124.Analog_18  # Grant read access to input signal Analog_18 to the runnable
            DRP_RP_CAN_RT_820b24_Analog_12: accessed-variable=RP_CAN_RT_820b24.Analog_12  # Grant read access to input signal Analog_12 to the runnable
            DRP_RP_CAN_RT_820a24_Analog_11: accessed-variable=RP_CAN_RT_820a24.Analog_11  # Grant read access to input signal Analog_11 to the runnable
            DRP_RP_CAN_RT_820924_Analog_10: accessed-variable=RP_CAN_RT_820924.Analog_10  # Grant read access to input signal Analog_10 to the runnable
            DRP_RP_CAN_RT_820824_Analog_9: accessed-variable=RP_CAN_RT_820824.Analog_9  # Grant read access to input signal Analog_9 to the runnable
            DRP_RP_CAN_RT_820724_Analog_8: accessed-variable=RP_CAN_RT_820724.Analog_8  # Grant read access to input signal Analog_8 to the runnable
            DRP_RP_CAN_RT_820624_Analog_7: accessed-variable=RP_CAN_RT_820624.Analog_7  # Grant read access to input signal Analog_7 to the runnable
            DRP_RP_CAN_RT_820524_Analog_6: accessed-variable=RP_CAN_RT_820524.Analog_6  # Grant read access to input signal Analog_6 to the runnable
            DRP_RP_CAN_RT_820424_Analog_5: accessed-variable=RP_CAN_RT_820424.Analog_5  # Grant read access to input signal Analog_5 to the runnable
            DRP_RP_CAN_RT_820324_Analog_4: accessed-variable=RP_CAN_RT_820324.Analog_4  # Grant read access to input signal Analog_4 to the runnable
            DRP_RP_CAN_RT_820224_Analog_3: accessed-variable=RP_CAN_RT_820224.Analog_3  # Grant read access to input signal Analog_3 to the runnable
            DRP_RP_CAN_RT_820124_Analog_2: accessed-variable=RP_CAN_RT_820124.Analog_2  # Grant read access to input signal Analog_2 to the runnable
            DRP_RP_CAN_RT_820024_Analog_1: accessed-variable=RP_CAN_RT_820024.Analog_1  # Grant read access to input signal Analog_1 to the runnable
            DRP_RP_CAN_RT_800024_Validity_Accel_Longitudinal: accessed-variable=RP_CAN_RT_800024.Validity_Accel_Longitudinal  # Grant read access to input signal Validity_Accel_Longitudinal to the runnable
            DRP_RP_CAN_RT_800024_Validity_Accel_Lateral: accessed-variable=RP_CAN_RT_800024.Validity_Accel_Lateral  # Grant read access to input signal Validity_Accel_Lateral to the runnable
            DRP_RP_CAN_RT_800024_Validity_Accel_Vertical: accessed-variable=RP_CAN_RT_800024.Validity_Accel_Vertical  # Grant read access to input signal Validity_Accel_Vertical to the runnable
            DRP_RP_CAN_RT_800024_Accuracy_Accel: accessed-variable=RP_CAN_RT_800024.Accuracy_Accel  # Grant read access to input signal Accuracy_Accel to the runnable
            DRP_RP_CAN_RT_800024_Accel_Longitudinal: accessed-variable=RP_CAN_RT_800024.Accel_Longitudinal  # Grant read access to input signal Accel_Longitudinal to the runnable
            DRP_RP_CAN_RT_800024_Accel_Lateral: accessed-variable=RP_CAN_RT_800024.Accel_Lateral  # Grant read access to input signal Accel_Lateral to the runnable
            DRP_RP_CAN_RT_800024_Accel_Vertical: accessed-variable=RP_CAN_RT_800024.Accel_Vertical  # Grant read access to input signal Accel_Vertical to the runnable
            DRP_RP_CAN_RT_8f3222_Virtual_4_Vel_NED_D: accessed-variable=RP_CAN_RT_8f3222.Virtual_4_Vel_NED_D  # Grant read access to input signal Virtual_4_Vel_NED_D to the runnable
            DRP_RP_CAN_RT_8f3222_Virtual_4_Heading: accessed-variable=RP_CAN_RT_8f3222.Virtual_4_Heading  # Grant read access to input signal Virtual_4_Heading to the runnable
            DRP_RP_CAN_RT_8f3222_Virtual_4_Slip: accessed-variable=RP_CAN_RT_8f3222.Virtual_4_Slip  # Grant read access to input signal Virtual_4_Slip to the runnable
            DRP_RP_CAN_RT_8f3122_Virtual_4_Vel_NED_N: accessed-variable=RP_CAN_RT_8f3122.Virtual_4_Vel_NED_N  # Grant read access to input signal Virtual_4_Vel_NED_N to the runnable
            DRP_RP_CAN_RT_8f3122_Virtual_4_Vel_NED_E: accessed-variable=RP_CAN_RT_8f3122.Virtual_4_Vel_NED_E  # Grant read access to input signal Virtual_4_Vel_NED_E to the runnable
            DRP_RP_CAN_RT_8f3022_Virtual_4_Offset_X: accessed-variable=RP_CAN_RT_8f3022.Virtual_4_Offset_X  # Grant read access to input signal Virtual_4_Offset_X to the runnable
            DRP_RP_CAN_RT_8f3022_Virtual_4_Offset_Y: accessed-variable=RP_CAN_RT_8f3022.Virtual_4_Offset_Y  # Grant read access to input signal Virtual_4_Offset_Y to the runnable
            DRP_RP_CAN_RT_8f3022_Virtual_4_Offset_Z: accessed-variable=RP_CAN_RT_8f3022.Virtual_4_Offset_Z  # Grant read access to input signal Virtual_4_Offset_Z to the runnable
            DRP_RP_CAN_RT_8f2222_Virtual_3_Vel_NED_D: accessed-variable=RP_CAN_RT_8f2222.Virtual_3_Vel_NED_D  # Grant read access to input signal Virtual_3_Vel_NED_D to the runnable
            DRP_RP_CAN_RT_8f2222_Virtual_3_Heading: accessed-variable=RP_CAN_RT_8f2222.Virtual_3_Heading  # Grant read access to input signal Virtual_3_Heading to the runnable
            DRP_RP_CAN_RT_8f2222_Virtual_3_Slip: accessed-variable=RP_CAN_RT_8f2222.Virtual_3_Slip  # Grant read access to input signal Virtual_3_Slip to the runnable
            DRP_RP_CAN_RT_8f2122_Virtual_3_Vel_NED_N: accessed-variable=RP_CAN_RT_8f2122.Virtual_3_Vel_NED_N  # Grant read access to input signal Virtual_3_Vel_NED_N to the runnable
            DRP_RP_CAN_RT_8f2122_Virtual_3_Vel_NED_E: accessed-variable=RP_CAN_RT_8f2122.Virtual_3_Vel_NED_E  # Grant read access to input signal Virtual_3_Vel_NED_E to the runnable
            DRP_RP_CAN_RT_8f2022_Virtual_3_Offset_X: accessed-variable=RP_CAN_RT_8f2022.Virtual_3_Offset_X  # Grant read access to input signal Virtual_3_Offset_X to the runnable
            DRP_RP_CAN_RT_8f2022_Virtual_3_Offset_Y: accessed-variable=RP_CAN_RT_8f2022.Virtual_3_Offset_Y  # Grant read access to input signal Virtual_3_Offset_Y to the runnable
            DRP_RP_CAN_RT_8f2022_Virtual_3_Offset_Z: accessed-variable=RP_CAN_RT_8f2022.Virtual_3_Offset_Z  # Grant read access to input signal Virtual_3_Offset_Z to the runnable
            DRP_RP_CAN_RT_8f1222_Virtual_2_Vel_NED_D: accessed-variable=RP_CAN_RT_8f1222.Virtual_2_Vel_NED_D  # Grant read access to input signal Virtual_2_Vel_NED_D to the runnable
            DRP_RP_CAN_RT_8f1222_Virtual_2_Heading: accessed-variable=RP_CAN_RT_8f1222.Virtual_2_Heading  # Grant read access to input signal Virtual_2_Heading to the runnable
            DRP_RP_CAN_RT_8f1222_Virtual_2_Slip: accessed-variable=RP_CAN_RT_8f1222.Virtual_2_Slip  # Grant read access to input signal Virtual_2_Slip to the runnable
            DRP_RP_CAN_RT_8f1122_Virtual_2_Vel_NED_N: accessed-variable=RP_CAN_RT_8f1122.Virtual_2_Vel_NED_N  # Grant read access to input signal Virtual_2_Vel_NED_N to the runnable
            DRP_RP_CAN_RT_8f1122_Virtual_2_Vel_NED_E: accessed-variable=RP_CAN_RT_8f1122.Virtual_2_Vel_NED_E  # Grant read access to input signal Virtual_2_Vel_NED_E to the runnable
            DRP_RP_CAN_RT_8f1022_Virtual_2_Offset_X: accessed-variable=RP_CAN_RT_8f1022.Virtual_2_Offset_X  # Grant read access to input signal Virtual_2_Offset_X to the runnable
            DRP_RP_CAN_RT_8f1022_Virtual_2_Offset_Y: accessed-variable=RP_CAN_RT_8f1022.Virtual_2_Offset_Y  # Grant read access to input signal Virtual_2_Offset_Y to the runnable
            DRP_RP_CAN_RT_8f1022_Virtual_2_Offset_Z: accessed-variable=RP_CAN_RT_8f1022.Virtual_2_Offset_Z  # Grant read access to input signal Virtual_2_Offset_Z to the runnable
            DRP_RP_CAN_RT_8f0222_Virtual_1_Vel_NED_D: accessed-variable=RP_CAN_RT_8f0222.Virtual_1_Vel_NED_D  # Grant read access to input signal Virtual_1_Vel_NED_D to the runnable
            DRP_RP_CAN_RT_8f0222_Virtual_1_Heading: accessed-variable=RP_CAN_RT_8f0222.Virtual_1_Heading  # Grant read access to input signal Virtual_1_Heading to the runnable
            DRP_RP_CAN_RT_8f0222_Virtual_1_Slip: accessed-variable=RP_CAN_RT_8f0222.Virtual_1_Slip  # Grant read access to input signal Virtual_1_Slip to the runnable
            DRP_RP_CAN_RT_8f0122_Virtual_1_Vel_NED_N: accessed-variable=RP_CAN_RT_8f0122.Virtual_1_Vel_NED_N  # Grant read access to input signal Virtual_1_Vel_NED_N to the runnable
            DRP_RP_CAN_RT_8f0122_Virtual_1_Vel_NED_E: accessed-variable=RP_CAN_RT_8f0122.Virtual_1_Vel_NED_E  # Grant read access to input signal Virtual_1_Vel_NED_E to the runnable
            DRP_RP_CAN_RT_8f0022_Virtual_1_Offset_X: accessed-variable=RP_CAN_RT_8f0022.Virtual_1_Offset_X  # Grant read access to input signal Virtual_1_Offset_X to the runnable
            DRP_RP_CAN_RT_8f0022_Virtual_1_Offset_Y: accessed-variable=RP_CAN_RT_8f0022.Virtual_1_Offset_Y  # Grant read access to input signal Virtual_1_Offset_Y to the runnable
            DRP_RP_CAN_RT_8f0022_Virtual_1_Offset_Z: accessed-variable=RP_CAN_RT_8f0022.Virtual_1_Offset_Z  # Grant read access to input signal Virtual_1_Offset_Z to the runnable
            DRP_RP_CAN_RT_8e1622_Validity_INS_Slip: accessed-variable=RP_CAN_RT_8e1622.Validity_INS_Slip  # Grant read access to input signal Validity_INS_Slip to the runnable
            DRP_RP_CAN_RT_8e1622_Validity_INS_Squat: accessed-variable=RP_CAN_RT_8e1622.Validity_INS_Squat  # Grant read access to input signal Validity_INS_Squat to the runnable
            DRP_RP_CAN_RT_8e1622_Accuracy_INS_Slip: accessed-variable=RP_CAN_RT_8e1622.Accuracy_INS_Slip  # Grant read access to input signal Accuracy_INS_Slip to the runnable
            DRP_RP_CAN_RT_8e1622_INS_Slip: accessed-variable=RP_CAN_RT_8e1622.INS_Slip  # Grant read access to input signal INS_Slip to the runnable
            DRP_RP_CAN_RT_8e1622_Accuracy_INS_Squat: accessed-variable=RP_CAN_RT_8e1622.Accuracy_INS_Squat  # Grant read access to input signal Accuracy_INS_Squat to the runnable
            DRP_RP_CAN_RT_8e1622_INS_Squat: accessed-variable=RP_CAN_RT_8e1622.INS_Squat  # Grant read access to input signal INS_Squat to the runnable
            DRP_RP_CAN_RT_8e1322_Validity_INS_Vel_ECEF_Y: accessed-variable=RP_CAN_RT_8e1322.Validity_INS_Vel_ECEF_Y  # Grant read access to input signal Validity_INS_Vel_ECEF_Y to the runnable
            DRP_RP_CAN_RT_8e1322_Validity_INS_Vel_ECEF_Z: accessed-variable=RP_CAN_RT_8e1322.Validity_INS_Vel_ECEF_Z  # Grant read access to input signal Validity_INS_Vel_ECEF_Z to the runnable
            DRP_RP_CAN_RT_8e1322_INS_Vel_ECEF_Y: accessed-variable=RP_CAN_RT_8e1322.INS_Vel_ECEF_Y  # Grant read access to input signal INS_Vel_ECEF_Y to the runnable
            DRP_RP_CAN_RT_8e1322_INS_Vel_ECEF_Z: accessed-variable=RP_CAN_RT_8e1322.INS_Vel_ECEF_Z  # Grant read access to input signal INS_Vel_ECEF_Z to the runnable
            DRP_RP_CAN_RT_8e1222_Validity_INS_Vel_ECEF_X: accessed-variable=RP_CAN_RT_8e1222.Validity_INS_Vel_ECEF_X  # Grant read access to input signal Validity_INS_Vel_ECEF_X to the runnable
            DRP_RP_CAN_RT_8e1222_Accuracy_INS_Vel_ECEF_X: accessed-variable=RP_CAN_RT_8e1222.Accuracy_INS_Vel_ECEF_X  # Grant read access to input signal Accuracy_INS_Vel_ECEF_X to the runnable
            DRP_RP_CAN_RT_8e1222_Accuracy_INS_Vel_ECEF_Y: accessed-variable=RP_CAN_RT_8e1222.Accuracy_INS_Vel_ECEF_Y  # Grant read access to input signal Accuracy_INS_Vel_ECEF_Y to the runnable
            DRP_RP_CAN_RT_8e1222_Accuracy_INS_Vel_ECEF_Z: accessed-variable=RP_CAN_RT_8e1222.Accuracy_INS_Vel_ECEF_Z  # Grant read access to input signal Accuracy_INS_Vel_ECEF_Z to the runnable
            DRP_RP_CAN_RT_8e1222_INS_Vel_ECEF_X: accessed-variable=RP_CAN_RT_8e1222.INS_Vel_ECEF_X  # Grant read access to input signal INS_Vel_ECEF_X to the runnable
            DRP_RP_CAN_RT_8e1122_Validity_INS_Vel_NED_D: accessed-variable=RP_CAN_RT_8e1122.Validity_INS_Vel_NED_D  # Grant read access to input signal Validity_INS_Vel_NED_D to the runnable
            DRP_RP_CAN_RT_8e1122_Accuracy_INS_Vel_D: accessed-variable=RP_CAN_RT_8e1122.Accuracy_INS_Vel_D  # Grant read access to input signal Accuracy_INS_Vel_D to the runnable
            DRP_RP_CAN_RT_8e1122_INS_Vel_NED_D: accessed-variable=RP_CAN_RT_8e1122.INS_Vel_NED_D  # Grant read access to input signal INS_Vel_NED_D to the runnable
            DRP_RP_CAN_RT_8e1022_Validity_INS_Vel_NED_N: accessed-variable=RP_CAN_RT_8e1022.Validity_INS_Vel_NED_N  # Grant read access to input signal Validity_INS_Vel_NED_N to the runnable
            DRP_RP_CAN_RT_8e1022_Validity_INS_Vel_NED_E: accessed-variable=RP_CAN_RT_8e1022.Validity_INS_Vel_NED_E  # Grant read access to input signal Validity_INS_Vel_NED_E to the runnable
            DRP_RP_CAN_RT_8e1022_Accuracy_INS_Vel_NE: accessed-variable=RP_CAN_RT_8e1022.Accuracy_INS_Vel_NE  # Grant read access to input signal Accuracy_INS_Vel_NE to the runnable
            DRP_RP_CAN_RT_8e1022_INS_Vel_NED_N: accessed-variable=RP_CAN_RT_8e1022.INS_Vel_NED_N  # Grant read access to input signal INS_Vel_NED_N to the runnable
            DRP_RP_CAN_RT_8e1022_INS_Vel_NED_E: accessed-variable=RP_CAN_RT_8e1022.INS_Vel_NED_E  # Grant read access to input signal INS_Vel_NED_E to the runnable
            DRP_RP_CAN_RT_8e0522_INS_Pos_ECEF_Y: accessed-variable=RP_CAN_RT_8e0522.INS_Pos_ECEF_Y  # Grant read access to input signal INS_Pos_ECEF_Y to the runnable
            DRP_RP_CAN_RT_8e0522_INS_Pos_ECEF_Z: accessed-variable=RP_CAN_RT_8e0522.INS_Pos_ECEF_Z  # Grant read access to input signal INS_Pos_ECEF_Z to the runnable
            DRP_RP_CAN_RT_8e0422_Validity_INS_Pos_ECEF_X: accessed-variable=RP_CAN_RT_8e0422.Validity_INS_Pos_ECEF_X  # Grant read access to input signal Validity_INS_Pos_ECEF_X to the runnable
            DRP_RP_CAN_RT_8e0422_Validity_INS_Pos_ECEF_Y: accessed-variable=RP_CAN_RT_8e0422.Validity_INS_Pos_ECEF_Y  # Grant read access to input signal Validity_INS_Pos_ECEF_Y to the runnable
            DRP_RP_CAN_RT_8e0422_Validity_INS_Pos_ECEF_Z: accessed-variable=RP_CAN_RT_8e0422.Validity_INS_Pos_ECEF_Z  # Grant read access to input signal Validity_INS_Pos_ECEF_Z to the runnable
            DRP_RP_CAN_RT_8e0422_Accuracy_INS_Pos_ECEF_X: accessed-variable=RP_CAN_RT_8e0422.Accuracy_INS_Pos_ECEF_X  # Grant read access to input signal Accuracy_INS_Pos_ECEF_X to the runnable
            DRP_RP_CAN_RT_8e0422_Accuracy_INS_Pos_ECEF_Y: accessed-variable=RP_CAN_RT_8e0422.Accuracy_INS_Pos_ECEF_Y  # Grant read access to input signal Accuracy_INS_Pos_ECEF_Y to the runnable
            DRP_RP_CAN_RT_8e0422_Accuracy_INS_Pos_ECEF_Z: accessed-variable=RP_CAN_RT_8e0422.Accuracy_INS_Pos_ECEF_Z  # Grant read access to input signal Accuracy_INS_Pos_ECEF_Z to the runnable
            DRP_RP_CAN_RT_8e0422_INS_Pos_ECEF_X: accessed-variable=RP_CAN_RT_8e0422.INS_Pos_ECEF_X  # Grant read access to input signal INS_Pos_ECEF_X to the runnable
            DRP_RP_CAN_RT_8e0322_INS_Pos_LLH_Longitude: accessed-variable=RP_CAN_RT_8e0322.INS_Pos_LLH_Longitude  # Grant read access to input signal INS_Pos_LLH_Longitude to the runnable
            DRP_RP_CAN_RT_8e0322_INS_Pos_LLH_Altitude: accessed-variable=RP_CAN_RT_8e0322.INS_Pos_LLH_Altitude  # Grant read access to input signal INS_Pos_LLH_Altitude to the runnable
            DRP_RP_CAN_RT_8e0222_Validity_INS_Pos_LLH_Latitude: accessed-variable=RP_CAN_RT_8e0222.Validity_INS_Pos_LLH_Latitude  # Grant read access to input signal Validity_INS_Pos_LLH_Latitude to the runnable
            DRP_RP_CAN_RT_8e0222_Validity_INS_Pos_LLH_Longitude: accessed-variable=RP_CAN_RT_8e0222.Validity_INS_Pos_LLH_Longitude  # Grant read access to input signal Validity_INS_Pos_LLH_Longitude to the runnable
            DRP_RP_CAN_RT_8e0222_Validity_INS_Pos_LLH_Altitude: accessed-variable=RP_CAN_RT_8e0222.Validity_INS_Pos_LLH_Altitude  # Grant read access to input signal Validity_INS_Pos_LLH_Altitude to the runnable
            DRP_RP_CAN_RT_8e0222_Accuracy_INS_Pos_LLH_Latitude: accessed-variable=RP_CAN_RT_8e0222.Accuracy_INS_Pos_LLH_Latitude  # Grant read access to input signal Accuracy_INS_Pos_LLH_Latitude to the runnable
            DRP_RP_CAN_RT_8e0222_Accuracy_INS_Pos_LLH_Longitude: accessed-variable=RP_CAN_RT_8e0222.Accuracy_INS_Pos_LLH_Longitude  # Grant read access to input signal Accuracy_INS_Pos_LLH_Longitude to the runnable
            DRP_RP_CAN_RT_8e0222_Accuracy_INS_Pos_LLH_Altitude: accessed-variable=RP_CAN_RT_8e0222.Accuracy_INS_Pos_LLH_Altitude  # Grant read access to input signal Accuracy_INS_Pos_LLH_Altitude to the runnable
            DRP_RP_CAN_RT_8e0222_INS_Pos_LLH_Latitude: accessed-variable=RP_CAN_RT_8e0222.INS_Pos_LLH_Latitude  # Grant read access to input signal INS_Pos_LLH_Latitude to the runnable
            DRP_RP_CAN_RT_8e1522_Validity_INS_Heading: accessed-variable=RP_CAN_RT_8e1522.Validity_INS_Heading  # Grant read access to input signal Validity_INS_Heading to the runnable
            DRP_RP_CAN_RT_8e1522_Validity_INS_Gradient: accessed-variable=RP_CAN_RT_8e1522.Validity_INS_Gradient  # Grant read access to input signal Validity_INS_Gradient to the runnable
            DRP_RP_CAN_RT_8e1522_Accuracy_INS_Heading: accessed-variable=RP_CAN_RT_8e1522.Accuracy_INS_Heading  # Grant read access to input signal Accuracy_INS_Heading to the runnable
            DRP_RP_CAN_RT_8e1522_INS_Heading_2: accessed-variable=RP_CAN_RT_8e1522.INS_Heading_2  # Grant read access to input signal INS_Heading_2 to the runnable
            DRP_RP_CAN_RT_8e1522_Accuracy_INS_Gradient: accessed-variable=RP_CAN_RT_8e1522.Accuracy_INS_Gradient  # Grant read access to input signal Accuracy_INS_Gradient to the runnable
            DRP_RP_CAN_RT_8e1522_INS_Gradient: accessed-variable=RP_CAN_RT_8e1522.INS_Gradient  # Grant read access to input signal INS_Gradient to the runnable
            DRP_RP_CAN_RT_8e1422_Validity_INS_Heading: accessed-variable=RP_CAN_RT_8e1422.Validity_INS_Heading  # Grant read access to input signal Validity_INS_Heading to the runnable
            DRP_RP_CAN_RT_8e1422_Validity_INS_Gradient: accessed-variable=RP_CAN_RT_8e1422.Validity_INS_Gradient  # Grant read access to input signal Validity_INS_Gradient to the runnable
            DRP_RP_CAN_RT_8e1422_Accuracy_INS_Heading: accessed-variable=RP_CAN_RT_8e1422.Accuracy_INS_Heading  # Grant read access to input signal Accuracy_INS_Heading to the runnable
            DRP_RP_CAN_RT_8e1422_INS_Heading: accessed-variable=RP_CAN_RT_8e1422.INS_Heading  # Grant read access to input signal INS_Heading to the runnable
            DRP_RP_CAN_RT_8e1422_Accuracy_INS_Gradient: accessed-variable=RP_CAN_RT_8e1422.Accuracy_INS_Gradient  # Grant read access to input signal Accuracy_INS_Gradient to the runnable
            DRP_RP_CAN_RT_8e1422_INS_Gradient: accessed-variable=RP_CAN_RT_8e1422.INS_Gradient  # Grant read access to input signal INS_Gradient to the runnable
            DRP_RP_CAN_RT_8e0022_INS_Status: accessed-variable=RP_CAN_RT_8e0022.INS_Status  # Grant read access to input signal INS_Status to the runnable
            DRP_RP_CAN_RT_8e0122_Validity_Yaw: accessed-variable=RP_CAN_RT_8e0122.Validity_Yaw  # Grant read access to input signal Validity_Yaw to the runnable
            DRP_RP_CAN_RT_8e0122_Validity_Pitch: accessed-variable=RP_CAN_RT_8e0122.Validity_Pitch  # Grant read access to input signal Validity_Pitch to the runnable
            DRP_RP_CAN_RT_8e0122_Validity_Roll: accessed-variable=RP_CAN_RT_8e0122.Validity_Roll  # Grant read access to input signal Validity_Roll to the runnable
            DRP_RP_CAN_RT_8e0122_Accuracy_Attitude: accessed-variable=RP_CAN_RT_8e0122.Accuracy_Attitude  # Grant read access to input signal Accuracy_Attitude to the runnable
            DRP_RP_CAN_RT_8e0122_Attitude_Yaw: accessed-variable=RP_CAN_RT_8e0122.Attitude_Yaw  # Grant read access to input signal Attitude_Yaw to the runnable
            DRP_RP_CAN_RT_8e0122_Attitude_Pitch: accessed-variable=RP_CAN_RT_8e0122.Attitude_Pitch  # Grant read access to input signal Attitude_Pitch to the runnable
            DRP_RP_CAN_RT_8e0122_Attitude_Roll: accessed-variable=RP_CAN_RT_8e0122.Attitude_Roll  # Grant read access to input signal Attitude_Roll to the runnable
            DRP_RP_CAN_RT_8d0122_Validity_Status_Timestamp: accessed-variable=RP_CAN_RT_8d0122.Validity_Status_Timestamp  # Grant read access to input signal Validity_Status_Timestamp to the runnable
            DRP_RP_CAN_RT_8d0122_Status_Analogue_{1..4}: accessed-variable=RP_CAN_RT_8d0122.Status_Analogue_{1..4}  # Grant read access to input signal Status_Analogue_{1..4} to the runnable
            DRP_RP_CAN_RT_8d0122_Status_Pulse_Output: accessed-variable=RP_CAN_RT_8d0122.Status_Pulse_Output  # Grant read access to input signal Status_Pulse_Output to the runnable
            DRP_RP_CAN_RT_8d0122_Status_Serial_Output_1: accessed-variable=RP_CAN_RT_8d0122.Status_Serial_Output_1  # Grant read access to input signal Status_Serial_Output_1 to the runnable
            DRP_RP_CAN_RT_8d0122_Status_Serial_Output_2: accessed-variable=RP_CAN_RT_8d0122.Status_Serial_Output_2  # Grant read access to input signal Status_Serial_Output_2 to the runnable
            DRP_RP_CAN_RT_8d0122_Status_Trigger: accessed-variable=RP_CAN_RT_8d0122.Status_Trigger  # Grant read access to input signal Status_Trigger to the runnable
            DRP_RP_CAN_RT_8d0122_GPS_Time: accessed-variable=RP_CAN_RT_8d0122.GPS_Time  # Grant read access to input signal GPS_Time to the runnable
            DRP_RP_CAN_RT_8c1622_Validity_GPS_Heading: accessed-variable=RP_CAN_RT_8c1622.Validity_GPS_Heading  # Grant read access to input signal Validity_GPS_Heading to the runnable
            DRP_RP_CAN_RT_8c1622_Validity_GPS_Gradient: accessed-variable=RP_CAN_RT_8c1622.Validity_GPS_Gradient  # Grant read access to input signal Validity_GPS_Gradient to the runnable
            DRP_RP_CAN_RT_8c1622_Accuracy_GPS_Heading: accessed-variable=RP_CAN_RT_8c1622.Accuracy_GPS_Heading  # Grant read access to input signal Accuracy_GPS_Heading to the runnable
            DRP_RP_CAN_RT_8c1622_GPS_Heading_2: accessed-variable=RP_CAN_RT_8c1622.GPS_Heading_2  # Grant read access to input signal GPS_Heading_2 to the runnable
            DRP_RP_CAN_RT_8c1622_Accuracy_GPS_Gradient: accessed-variable=RP_CAN_RT_8c1622.Accuracy_GPS_Gradient  # Grant read access to input signal Accuracy_GPS_Gradient to the runnable
            DRP_RP_CAN_RT_8c1622_GPS_Gradient: accessed-variable=RP_CAN_RT_8c1622.GPS_Gradient  # Grant read access to input signal GPS_Gradient to the runnable
            DRP_RP_CAN_RT_802122_Validity_Cumulative_Time: accessed-variable=RP_CAN_RT_802122.Validity_Cumulative_Time  # Grant read access to input signal Validity_Cumulative_Time to the runnable
            DRP_RP_CAN_RT_802122_Validity_Cumulative_Distance: accessed-variable=RP_CAN_RT_802122.Validity_Cumulative_Distance  # Grant read access to input signal Validity_Cumulative_Distance to the runnable
            DRP_RP_CAN_RT_802122_Cumulative_Time: accessed-variable=RP_CAN_RT_802122.Cumulative_Time  # Grant read access to input signal Cumulative_Time to the runnable
            DRP_RP_CAN_RT_802122_Cumulative_Distance: accessed-variable=RP_CAN_RT_802122.Cumulative_Distance  # Grant read access to input signal Cumulative_Distance to the runnable
            DRP_RP_CAN_RT_802022_Validity_Cumulative_Time: accessed-variable=RP_CAN_RT_802022.Validity_Cumulative_Time  # Grant read access to input signal Validity_Cumulative_Time to the runnable
            DRP_RP_CAN_RT_802022_Validity_Cumulative_Distance: accessed-variable=RP_CAN_RT_802022.Validity_Cumulative_Distance  # Grant read access to input signal Validity_Cumulative_Distance to the runnable
            DRP_RP_CAN_RT_802022_Cumulative_Time: accessed-variable=RP_CAN_RT_802022.Cumulative_Time  # Grant read access to input signal Cumulative_Time to the runnable
            DRP_RP_CAN_RT_802022_Cumulative_Distance: accessed-variable=RP_CAN_RT_802022.Cumulative_Distance  # Grant read access to input signal Cumulative_Distance to the runnable
            DRP_RP_CAN_RT_8d0022_Validity_Trigger_Timestamp: accessed-variable=RP_CAN_RT_8d0022.Validity_Trigger_Timestamp  # Grant read access to input signal Validity_Trigger_Timestamp to the runnable
            DRP_RP_CAN_RT_8d0022_Accuracy_Trigger_Timestamp: accessed-variable=RP_CAN_RT_8d0022.Accuracy_Trigger_Timestamp  # Grant read access to input signal Accuracy_Trigger_Timestamp to the runnable
            DRP_RP_CAN_RT_8d0022_Trigger_Number: accessed-variable=RP_CAN_RT_8d0022.Trigger_Number  # Grant read access to input signal Trigger_Number to the runnable
            DRP_RP_CAN_RT_8d0022_Trigger_Timestamp_Type: accessed-variable=RP_CAN_RT_8d0022.Trigger_Timestamp_Type  # Grant read access to input signal Trigger_Timestamp_Type to the runnable
            DRP_RP_CAN_RT_8d0022_GPS_High_Resolution_Time: accessed-variable=RP_CAN_RT_8d0022.GPS_High_Resolution_Time  # Grant read access to input signal GPS_High_Resolution_Time to the runnable
            DRP_RP_CAN_RT_800121_Validity_Gyro_Rate_Yaw: accessed-variable=RP_CAN_RT_800121.Validity_Gyro_Rate_Yaw  # Grant read access to input signal Validity_Gyro_Rate_Yaw to the runnable
            DRP_RP_CAN_RT_800121_Validity_Gyro_Rate_Pitch: accessed-variable=RP_CAN_RT_800121.Validity_Gyro_Rate_Pitch  # Grant read access to input signal Validity_Gyro_Rate_Pitch to the runnable
            DRP_RP_CAN_RT_800121_Validity_Gyro_Rate_Roll: accessed-variable=RP_CAN_RT_800121.Validity_Gyro_Rate_Roll  # Grant read access to input signal Validity_Gyro_Rate_Roll to the runnable
            DRP_RP_CAN_RT_800121_Accuracy_Gyro_Rates: accessed-variable=RP_CAN_RT_800121.Accuracy_Gyro_Rates  # Grant read access to input signal Accuracy_Gyro_Rates to the runnable
            DRP_RP_CAN_RT_800121_Gyro_Rate_Yaw: accessed-variable=RP_CAN_RT_800121.Gyro_Rate_Yaw  # Grant read access to input signal Gyro_Rate_Yaw to the runnable
            DRP_RP_CAN_RT_800121_Gyro_Rate_Pitch: accessed-variable=RP_CAN_RT_800121.Gyro_Rate_Pitch  # Grant read access to input signal Gyro_Rate_Pitch to the runnable
            DRP_RP_CAN_RT_800121_Gyro_Rate_Roll: accessed-variable=RP_CAN_RT_800121.Gyro_Rate_Roll  # Grant read access to input signal Gyro_Rate_Roll to the runnable
            DRP_RP_CAN_RT_800021_Validity_Accel_Longitudinal: accessed-variable=RP_CAN_RT_800021.Validity_Accel_Longitudinal  # Grant read access to input signal Validity_Accel_Longitudinal to the runnable
            DRP_RP_CAN_RT_800021_Validity_Accel_Lateral: accessed-variable=RP_CAN_RT_800021.Validity_Accel_Lateral  # Grant read access to input signal Validity_Accel_Lateral to the runnable
            DRP_RP_CAN_RT_800021_Validity_Accel_Vertical: accessed-variable=RP_CAN_RT_800021.Validity_Accel_Vertical  # Grant read access to input signal Validity_Accel_Vertical to the runnable
            DRP_RP_CAN_RT_800021_Accuracy_Accel: accessed-variable=RP_CAN_RT_800021.Accuracy_Accel  # Grant read access to input signal Accuracy_Accel to the runnable
            DRP_RP_CAN_RT_800021_Accel_Longitudinal: accessed-variable=RP_CAN_RT_800021.Accel_Longitudinal  # Grant read access to input signal Accel_Longitudinal to the runnable
            DRP_RP_CAN_RT_800021_Accel_Lateral: accessed-variable=RP_CAN_RT_800021.Accel_Lateral  # Grant read access to input signal Accel_Lateral to the runnable
            DRP_RP_CAN_RT_800021_Accel_Vertical: accessed-variable=RP_CAN_RT_800021.Accel_Vertical  # Grant read access to input signal Accel_Vertical to the runnable
            DRP_RP_CAN_RT_801022_Validity_Speed: accessed-variable=RP_CAN_RT_801022.Validity_Speed  # Grant read access to input signal Validity_Speed to the runnable
            DRP_RP_CAN_RT_801022_Accuracy_Speed: accessed-variable=RP_CAN_RT_801022.Accuracy_Speed  # Grant read access to input signal Accuracy_Speed to the runnable
            DRP_RP_CAN_RT_801022_Speed: accessed-variable=RP_CAN_RT_801022.Speed  # Grant read access to input signal Speed to the runnable
            DRP_RP_CAN_RT_8c2122_Validity_RTK_Slip: accessed-variable=RP_CAN_RT_8c2122.Validity_RTK_Slip  # Grant read access to input signal Validity_RTK_Slip to the runnable
            DRP_RP_CAN_RT_8c2122_Validity_RTK_Squat: accessed-variable=RP_CAN_RT_8c2122.Validity_RTK_Squat  # Grant read access to input signal Validity_RTK_Squat to the runnable
            DRP_RP_CAN_RT_8c2122_Validity_RTK_Baseline: accessed-variable=RP_CAN_RT_8c2122.Validity_RTK_Baseline  # Grant read access to input signal Validity_RTK_Baseline to the runnable
            DRP_RP_CAN_RT_8c2122_Accuracy_RTK_Baseline: accessed-variable=RP_CAN_RT_8c2122.Accuracy_RTK_Baseline  # Grant read access to input signal Accuracy_RTK_Baseline to the runnable
            DRP_RP_CAN_RT_8c2122_RTK_Slip: accessed-variable=RP_CAN_RT_8c2122.RTK_Slip  # Grant read access to input signal RTK_Slip to the runnable
            DRP_RP_CAN_RT_8c2122_RTK_Squat: accessed-variable=RP_CAN_RT_8c2122.RTK_Squat  # Grant read access to input signal RTK_Squat to the runnable
            DRP_RP_CAN_RT_8c2122_RTK_Baseline: accessed-variable=RP_CAN_RT_8c2122.RTK_Baseline  # Grant read access to input signal RTK_Baseline to the runnable
            DRP_RP_CAN_RT_8c2022_Validity_RTK_Yaw: accessed-variable=RP_CAN_RT_8c2022.Validity_RTK_Yaw  # Grant read access to input signal Validity_RTK_Yaw to the runnable
            DRP_RP_CAN_RT_8c2022_Validity_RTK_Pitch: accessed-variable=RP_CAN_RT_8c2022.Validity_RTK_Pitch  # Grant read access to input signal Validity_RTK_Pitch to the runnable
            DRP_RP_CAN_RT_8c2022_Validity_RTK_Roll: accessed-variable=RP_CAN_RT_8c2022.Validity_RTK_Roll  # Grant read access to input signal Validity_RTK_Roll to the runnable
            DRP_RP_CAN_RT_8c2022_Accuracy_RTK_Attitude: accessed-variable=RP_CAN_RT_8c2022.Accuracy_RTK_Attitude  # Grant read access to input signal Accuracy_RTK_Attitude to the runnable
            DRP_RP_CAN_RT_8c2022_RTK_Attitude_Yaw: accessed-variable=RP_CAN_RT_8c2022.RTK_Attitude_Yaw  # Grant read access to input signal RTK_Attitude_Yaw to the runnable
            DRP_RP_CAN_RT_8c2022_RTK_Attitude_Pitch: accessed-variable=RP_CAN_RT_8c2022.RTK_Attitude_Pitch  # Grant read access to input signal RTK_Attitude_Pitch to the runnable
            DRP_RP_CAN_RT_8c2022_RTK_Attitude_Roll: accessed-variable=RP_CAN_RT_8c2022.RTK_Attitude_Roll  # Grant read access to input signal RTK_Attitude_Roll to the runnable
            DRP_RP_CAN_RT_8c3022_Validity_GPS_Lateral_Accel: accessed-variable=RP_CAN_RT_8c3022.Validity_GPS_Lateral_Accel  # Grant read access to input signal Validity_GPS_Lateral_Accel to the runnable
            DRP_RP_CAN_RT_8c3022_Validity_GPS_Mcycle_Lean: accessed-variable=RP_CAN_RT_8c3022.Validity_GPS_Mcycle_Lean  # Grant read access to input signal Validity_GPS_Mcycle_Lean to the runnable
            DRP_RP_CAN_RT_8c3022_Accuracy_GPS_Lateral_Accel: accessed-variable=RP_CAN_RT_8c3022.Accuracy_GPS_Lateral_Accel  # Grant read access to input signal Accuracy_GPS_Lateral_Accel to the runnable
            DRP_RP_CAN_RT_8c3022_GPS_Lateral_Accel: accessed-variable=RP_CAN_RT_8c3022.GPS_Lateral_Accel  # Grant read access to input signal GPS_Lateral_Accel to the runnable
            DRP_RP_CAN_RT_8c3022_GPS_Mcycle_Lean_Angle: accessed-variable=RP_CAN_RT_8c3022.GPS_Mcycle_Lean_Angle  # Grant read access to input signal GPS_Mcycle_Lean_Angle to the runnable
            DRP_RP_CAN_RT_8c0022_GPS_Status: accessed-variable=RP_CAN_RT_8c0022.GPS_Status  # Grant read access to input signal GPS_Status to the runnable
            DRP_RP_CAN_RT_8c0022_Firmware_Version_Major: accessed-variable=RP_CAN_RT_8c0022.Firmware_Version_Major  # Grant read access to input signal Firmware_Version_Major to the runnable
            DRP_RP_CAN_RT_8c0022_Firmware_Version_Intermediate: accessed-variable=RP_CAN_RT_8c0022.Firmware_Version_Intermediate  # Grant read access to input signal Firmware_Version_Intermediate to the runnable
            DRP_RP_CAN_RT_8c0022_Firmware_Version_Minor: accessed-variable=RP_CAN_RT_8c0022.Firmware_Version_Minor  # Grant read access to input signal Firmware_Version_Minor to the runnable
            DRP_RP_CAN_RT_8c0022_GPS_nSv: accessed-variable=RP_CAN_RT_8c0022.GPS_nSv  # Grant read access to input signal GPS_nSv to the runnable
            DRP_RP_CAN_RT_8c0022_GPS_nSv_2: accessed-variable=RP_CAN_RT_8c0022.GPS_nSv_2  # Grant read access to input signal GPS_nSv_2 to the runnable
            DRP_RP_CAN_RT_8c0022_GPS_nSv_RTK: accessed-variable=RP_CAN_RT_8c0022.GPS_nSv_RTK  # Grant read access to input signal GPS_nSv_RTK to the runnable
            DRP_RP_CAN_RT_8c0022_RTK_Status: accessed-variable=RP_CAN_RT_8c0022.RTK_Status  # Grant read access to input signal RTK_Status to the runnable
            DRP_RP_CAN_RT_8c0522_GPS_Pos_ECEF_Y: accessed-variable=RP_CAN_RT_8c0522.GPS_Pos_ECEF_Y  # Grant read access to input signal GPS_Pos_ECEF_Y to the runnable
            DRP_RP_CAN_RT_8c0522_GPS_Pos_ECEF_Z: accessed-variable=RP_CAN_RT_8c0522.GPS_Pos_ECEF_Z  # Grant read access to input signal GPS_Pos_ECEF_Z to the runnable
            DRP_RP_CAN_RT_8c0422_Validity_GPS_Pos_ECEF_X: accessed-variable=RP_CAN_RT_8c0422.Validity_GPS_Pos_ECEF_X  # Grant read access to input signal Validity_GPS_Pos_ECEF_X to the runnable
            DRP_RP_CAN_RT_8c0422_Validity_GPS_Pos_ECEF_Y: accessed-variable=RP_CAN_RT_8c0422.Validity_GPS_Pos_ECEF_Y  # Grant read access to input signal Validity_GPS_Pos_ECEF_Y to the runnable
            DRP_RP_CAN_RT_8c0422_Validity_GPS_Pos_ECEF_Z: accessed-variable=RP_CAN_RT_8c0422.Validity_GPS_Pos_ECEF_Z  # Grant read access to input signal Validity_GPS_Pos_ECEF_Z to the runnable
            DRP_RP_CAN_RT_8c0422_Accuracy_GPS_Pos_ECEF_X: accessed-variable=RP_CAN_RT_8c0422.Accuracy_GPS_Pos_ECEF_X  # Grant read access to input signal Accuracy_GPS_Pos_ECEF_X to the runnable
            DRP_RP_CAN_RT_8c0422_Accuracy_GPS_Pos_ECEF_Y: accessed-variable=RP_CAN_RT_8c0422.Accuracy_GPS_Pos_ECEF_Y  # Grant read access to input signal Accuracy_GPS_Pos_ECEF_Y to the runnable
            DRP_RP_CAN_RT_8c0422_Accuracy_GPS_Pos_ECEF_Z: accessed-variable=RP_CAN_RT_8c0422.Accuracy_GPS_Pos_ECEF_Z  # Grant read access to input signal Accuracy_GPS_Pos_ECEF_Z to the runnable
            DRP_RP_CAN_RT_8c0422_GPS_Pos_ECEF_X: accessed-variable=RP_CAN_RT_8c0422.GPS_Pos_ECEF_X  # Grant read access to input signal GPS_Pos_ECEF_X to the runnable
            DRP_RP_CAN_RT_8c0322_GPS_Pos_LLH_Longitude: accessed-variable=RP_CAN_RT_8c0322.GPS_Pos_LLH_Longitude  # Grant read access to input signal GPS_Pos_LLH_Longitude to the runnable
            DRP_RP_CAN_RT_8c0322_GPS_Pos_LLH_Altitude: accessed-variable=RP_CAN_RT_8c0322.GPS_Pos_LLH_Altitude  # Grant read access to input signal GPS_Pos_LLH_Altitude to the runnable
            DRP_RP_CAN_RT_8c0222_Validity_GPS_Pos_LLH_Latitude: accessed-variable=RP_CAN_RT_8c0222.Validity_GPS_Pos_LLH_Latitude  # Grant read access to input signal Validity_GPS_Pos_LLH_Latitude to the runnable
            DRP_RP_CAN_RT_8c0222_Validity_GPS_Pos_LLH_Longitude: accessed-variable=RP_CAN_RT_8c0222.Validity_GPS_Pos_LLH_Longitude  # Grant read access to input signal Validity_GPS_Pos_LLH_Longitude to the runnable
            DRP_RP_CAN_RT_8c0222_Validity_GPS_Pos_LLH_Altitude: accessed-variable=RP_CAN_RT_8c0222.Validity_GPS_Pos_LLH_Altitude  # Grant read access to input signal Validity_GPS_Pos_LLH_Altitude to the runnable
            DRP_RP_CAN_RT_8c0222_Accuracy_GPS_Pos_LLH_Latitude: accessed-variable=RP_CAN_RT_8c0222.Accuracy_GPS_Pos_LLH_Latitude  # Grant read access to input signal Accuracy_GPS_Pos_LLH_Latitude to the runnable
            DRP_RP_CAN_RT_8c0222_Accuracy_GPS_Pos_LLH_Longitude: accessed-variable=RP_CAN_RT_8c0222.Accuracy_GPS_Pos_LLH_Longitude  # Grant read access to input signal Accuracy_GPS_Pos_LLH_Longitude to the runnable
            DRP_RP_CAN_RT_8c0222_Accuracy_GPS_Pos_LLH_Altitude: accessed-variable=RP_CAN_RT_8c0222.Accuracy_GPS_Pos_LLH_Altitude  # Grant read access to input signal Accuracy_GPS_Pos_LLH_Altitude to the runnable
            DRP_RP_CAN_RT_8c0222_GPS_Pos_LLH_Latitude: accessed-variable=RP_CAN_RT_8c0222.GPS_Pos_LLH_Latitude  # Grant read access to input signal GPS_Pos_LLH_Latitude to the runnable
            DRP_RP_CAN_RT_8c1522_Validity_GPS_Heading: accessed-variable=RP_CAN_RT_8c1522.Validity_GPS_Heading  # Grant read access to input signal Validity_GPS_Heading to the runnable
            DRP_RP_CAN_RT_8c1522_Validity_GPS_Gradient: accessed-variable=RP_CAN_RT_8c1522.Validity_GPS_Gradient  # Grant read access to input signal Validity_GPS_Gradient to the runnable
            DRP_RP_CAN_RT_8c1522_Accuracy_GPS_Heading: accessed-variable=RP_CAN_RT_8c1522.Accuracy_GPS_Heading  # Grant read access to input signal Accuracy_GPS_Heading to the runnable
            DRP_RP_CAN_RT_8c1522_GPS_Heading: accessed-variable=RP_CAN_RT_8c1522.GPS_Heading  # Grant read access to input signal GPS_Heading to the runnable
            DRP_RP_CAN_RT_8c1522_Accuracy_GPS_Gradient: accessed-variable=RP_CAN_RT_8c1522.Accuracy_GPS_Gradient  # Grant read access to input signal Accuracy_GPS_Gradient to the runnable
            DRP_RP_CAN_RT_8c1522_GPS_Gradient: accessed-variable=RP_CAN_RT_8c1522.GPS_Gradient  # Grant read access to input signal GPS_Gradient to the runnable
            DRP_RP_CAN_RT_8c1422_Validity_GPS_Vel_ECEF_Y: accessed-variable=RP_CAN_RT_8c1422.Validity_GPS_Vel_ECEF_Y  # Grant read access to input signal Validity_GPS_Vel_ECEF_Y to the runnable
            DRP_RP_CAN_RT_8c1422_Validity_GPS_Vel_ECEF_Z: accessed-variable=RP_CAN_RT_8c1422.Validity_GPS_Vel_ECEF_Z  # Grant read access to input signal Validity_GPS_Vel_ECEF_Z to the runnable
            DRP_RP_CAN_RT_8c1422_GPS_Vel_ECEF_Y: accessed-variable=RP_CAN_RT_8c1422.GPS_Vel_ECEF_Y  # Grant read access to input signal GPS_Vel_ECEF_Y to the runnable
            DRP_RP_CAN_RT_8c1422_GPS_Vel_ECEF_Z: accessed-variable=RP_CAN_RT_8c1422.GPS_Vel_ECEF_Z  # Grant read access to input signal GPS_Vel_ECEF_Z to the runnable
            DRP_RP_CAN_RT_8c1322_Validity_GPS_Vel_ECEF_X: accessed-variable=RP_CAN_RT_8c1322.Validity_GPS_Vel_ECEF_X  # Grant read access to input signal Validity_GPS_Vel_ECEF_X to the runnable
            DRP_RP_CAN_RT_8c1322_Accuracy_GPS_Vel_ECEF_X: accessed-variable=RP_CAN_RT_8c1322.Accuracy_GPS_Vel_ECEF_X  # Grant read access to input signal Accuracy_GPS_Vel_ECEF_X to the runnable
            DRP_RP_CAN_RT_8c1322_Accuracy_GPS_Vel_ECEF_Y: accessed-variable=RP_CAN_RT_8c1322.Accuracy_GPS_Vel_ECEF_Y  # Grant read access to input signal Accuracy_GPS_Vel_ECEF_Y to the runnable
            DRP_RP_CAN_RT_8c1322_Accuracy_GPS_Vel_ECEF_Z: accessed-variable=RP_CAN_RT_8c1322.Accuracy_GPS_Vel_ECEF_Z  # Grant read access to input signal Accuracy_GPS_Vel_ECEF_Z to the runnable
            DRP_RP_CAN_RT_8c1322_GPS_Vel_ECEF_X: accessed-variable=RP_CAN_RT_8c1322.GPS_Vel_ECEF_X  # Grant read access to input signal GPS_Vel_ECEF_X to the runnable
            DRP_RP_CAN_RT_000_Validity_GPS_Vel_NED_D: accessed-variable=RP_CAN_RT_000.Validity_GPS_Vel_NED_D  # Grant read access to input signal Validity_GPS_Vel_NED_D to the runnable
            DRP_RP_CAN_RT_000_Accuracy_GPS_Vel_D: accessed-variable=RP_CAN_RT_000.Accuracy_GPS_Vel_D  # Grant read access to input signal Accuracy_GPS_Vel_D to the runnable
            DRP_RP_CAN_RT_000_GPS_Vel_NED_D: accessed-variable=RP_CAN_RT_000.GPS_Vel_NED_D  # Grant read access to input signal GPS_Vel_NED_D to the runnable
            DRP_RP_CAN_RT_1fffffff_Validity_GPS_Vel_NED_N: accessed-variable=RP_CAN_RT_1fffffff.Validity_GPS_Vel_NED_N  # Grant read access to input signal Validity_GPS_Vel_NED_N to the runnable
            DRP_RP_CAN_RT_1fffffff_Validity_GPS_Vel_NED_E: accessed-variable=RP_CAN_RT_1fffffff.Validity_GPS_Vel_NED_E  # Grant read access to input signal Validity_GPS_Vel_NED_E to the runnable
            DRP_RP_CAN_RT_1fffffff_Accuracy_GPS_Vel_NE: accessed-variable=RP_CAN_RT_1fffffff.Accuracy_GPS_Vel_NE  # Grant read access to input signal Accuracy_GPS_Vel_NE to the runnable
            DRP_RP_CAN_RT_1fffffff_GPS_Vel_NED_N: accessed-variable=RP_CAN_RT_1fffffff.GPS_Vel_NED_N  # Grant read access to input signal GPS_Vel_NED_N to the runnable
            DRP_RP_CAN_RT_1fffffff_GPS_Vel_NED_E: accessed-variable=RP_CAN_RT_1fffffff.GPS_Vel_NED_E  # Grant read access to input signal GPS_Vel_NED_E to the runnable
            DRP_RP_CAN_RT_71a_Validity_GPS_Speed_2D: accessed-variable=RP_CAN_RT_71a.Validity_GPS_Speed_2D  # Grant read access to input signal Validity_GPS_Speed_2D to the runnable
            DRP_RP_CAN_RT_71a_Validity_GPS_Speed_3D: accessed-variable=RP_CAN_RT_71a.Validity_GPS_Speed_3D  # Grant read access to input signal Validity_GPS_Speed_3D to the runnable
            DRP_RP_CAN_RT_71a_Accuracy_GPS_Speed: accessed-variable=RP_CAN_RT_71a.Accuracy_GPS_Speed  # Grant read access to input signal Accuracy_GPS_Speed to the runnable
            DRP_RP_CAN_RT_71a_GPS_Speed_2D: accessed-variable=RP_CAN_RT_71a.GPS_Speed_2D  # Grant read access to input signal GPS_Speed_2D to the runnable
            DRP_RP_CAN_RT_71a_GPS_Speed_3D: accessed-variable=RP_CAN_RT_71a.GPS_Speed_3D  # Grant read access to input signal GPS_Speed_3D to the runnable
            DRP_RP_CAN_RT_7ff_Validity_GPS_Time: accessed-variable=RP_CAN_RT_7ff.Validity_GPS_Time  # Grant read access to input signal Validity_GPS_Time to the runnable
            DRP_RP_CAN_RT_7ff_Validity_GPS_Week: accessed-variable=RP_CAN_RT_7ff.Validity_GPS_Week  # Grant read access to input signal Validity_GPS_Week to the runnable
            DRP_RP_CAN_RT_7ff_Accuracy_GPS_Time: accessed-variable=RP_CAN_RT_7ff.Accuracy_GPS_Time  # Grant read access to input signal Accuracy_GPS_Time to the runnable
            DRP_RP_CAN_RT_7ff_GPS_Time: accessed-variable=RP_CAN_RT_7ff.GPS_Time  # Grant read access to input signal GPS_Time to the runnable
            DRP_RP_CAN_RT_7ff_GPS_Week: accessed-variable=RP_CAN_RT_7ff.GPS_Week  # Grant read access to input signal GPS_Week to the runnable
            DRP_RP_CAN_RT_122_Validity_Accel_Longitudinal: accessed-variable=RP_CAN_RT_122.Validity_Accel_Longitudinal  # Grant read access to input signal Validity_Accel_Longitudinal to the runnable
            DRP_RP_CAN_RT_122_Validity_Accel_Lateral: accessed-variable=RP_CAN_RT_122.Validity_Accel_Lateral  # Grant read access to input signal Validity_Accel_Lateral to the runnable
            DRP_RP_CAN_RT_122_Validity_Accel_Vertical: accessed-variable=RP_CAN_RT_122.Validity_Accel_Vertical  # Grant read access to input signal Validity_Accel_Vertical to the runnable
            DRP_RP_CAN_RT_122_Accuracy_Accel: accessed-variable=RP_CAN_RT_122.Accuracy_Accel  # Grant read access to input signal Accuracy_Accel to the runnable
            DRP_RP_CAN_RT_122_Accel_Longitudinal: accessed-variable=RP_CAN_RT_122.Accel_Longitudinal  # Grant read access to input signal Accel_Longitudinal to the runnable
            DRP_RP_CAN_RT_122_Accel_Lateral: accessed-variable=RP_CAN_RT_122.Accel_Lateral  # Grant read access to input signal Accel_Lateral to the runnable
            DRP_RP_CAN_RT_122_Accel_Vertical: accessed-variable=RP_CAN_RT_122.Accel_Vertical  # Grant read access to input signal Accel_Vertical to the runnable
            DRP_RP_CAN_RT_800122_Validity_Gyro_Rate_Yaw: accessed-variable=RP_CAN_RT_800122.Validity_Gyro_Rate_Yaw  # Grant read access to input signal Validity_Gyro_Rate_Yaw to the runnable
            DRP_RP_CAN_RT_800122_Validity_Gyro_Rate_Pitch: accessed-variable=RP_CAN_RT_800122.Validity_Gyro_Rate_Pitch  # Grant read access to input signal Validity_Gyro_Rate_Pitch to the runnable
            DRP_RP_CAN_RT_800122_Validity_Gyro_Rate_Roll: accessed-variable=RP_CAN_RT_800122.Validity_Gyro_Rate_Roll  # Grant read access to input signal Validity_Gyro_Rate_Roll to the runnable
            DRP_RP_CAN_RT_800122_Accuracy_Gyro_Rates: accessed-variable=RP_CAN_RT_800122.Accuracy_Gyro_Rates  # Grant read access to input signal Accuracy_Gyro_Rates to the runnable
            DRP_RP_CAN_RT_800122_Gyro_Rate_Yaw: accessed-variable=RP_CAN_RT_800122.Gyro_Rate_Yaw  # Grant read access to input signal Gyro_Rate_Yaw to the runnable
            DRP_RP_CAN_RT_800122_Gyro_Rate_Pitch: accessed-variable=RP_CAN_RT_800122.Gyro_Rate_Pitch  # Grant read access to input signal Gyro_Rate_Pitch to the runnable
            DRP_RP_CAN_RT_800122_Gyro_Rate_Roll: accessed-variable=RP_CAN_RT_800122.Gyro_Rate_Roll  # Grant read access to input signal Gyro_Rate_Roll to the runnable
        data-send-points:
          18 x access:
            DSP_PP_CAN_RT_980625_IR_Temperature_{21..24}: accessed-variable=PP_CAN_RT_980625.IR_Temperature_{21..24}  # Grant write access to output signal IR_Temperature_{21..24} to the runnable
            DSP_PP_CAN_RT_980425_IR_Temperature_{13..16}: accessed-variable=PP_CAN_RT_980425.IR_Temperature_{13..16}  # Grant write access to output signal IR_Temperature_{13..16} to the runnable
            DSP_PP_CAN_RT_911e25_IR_Temperature_30: accessed-variable=PP_CAN_RT_911e25.IR_Temperature_30  # Grant write access to output signal IR_Temperature_30 to the runnable
            DSP_PP_CAN_RT_911a25_IR_Temperature_26: accessed-variable=PP_CAN_RT_911a25.IR_Temperature_26  # Grant write access to output signal IR_Temperature_26 to the runnable
            DSP_PP_CAN_RT_8d0422_Forward_Distance: accessed-variable=PP_CAN_RT_8d0422.Forward_Distance  # Grant write access to output signal Forward_Distance to the runnable
            DSP_PP_CAN_RT_8d0422_Deviation_Distance: accessed-variable=PP_CAN_RT_8d0422.Deviation_Distance  # Grant write access to output signal Deviation_Distance to the runnable
            DSP_PP_CAN_RT_8d0222_Validity_MFDD: accessed-variable=PP_CAN_RT_8d0222.Validity_MFDD  # Grant write access to output signal Validity_MFDD to the runnable
            DSP_PP_CAN_RT_8d0222_Validity_Average_Accel: accessed-variable=PP_CAN_RT_8d0222.Validity_Average_Accel  # Grant write access to output signal Validity_Average_Accel to the runnable
            DSP_PP_CAN_RT_8d0222_Validity_Triggered_Time: accessed-variable=PP_CAN_RT_8d0222.Validity_Triggered_Time  # Grant write access to output signal Validity_Triggered_Time to the runnable
            DSP_PP_CAN_RT_8d0222_MFDD: accessed-variable=PP_CAN_RT_8d0222.MFDD  # Grant write access to output signal MFDD to the runnable
            DSP_PP_CAN_RT_8d0222_Average_Accel: accessed-variable=PP_CAN_RT_8d0222.Average_Accel  # Grant write access to output signal Average_Accel to the runnable
            DSP_PP_CAN_RT_8d0222_Triggered_Time: accessed-variable=PP_CAN_RT_8d0222.Triggered_Time  # Grant write access to output signal Triggered_Time to the runnable
  data type mapping set cif_dataTypeMappingSet  # Data type mapping for all application data types, one for each signal of each bus. The application data type is mapped to the appropriate implementation type
    data-type-maps:
      application-data-type=cif_0x0d7_Validity_INS_Vel_Forwards_t, implementation-data-type=boolean
      application-data-type=cif_0x0d7_Validity_INS_Vel_Sideways_t, implementation-data-type=boolean
      application-data-type=cif_0x0d7_Bit4_t, implementation-data-type=boolean
      application-data-type=cif_0x0d7_Bit7_t, implementation-data-type=boolean
      application-data-type=cif_0x0d7_Byte2_Bit0_t, implementation-data-type=boolean
      application-data-type=cif_0x0d7_INS_Vel_Sideways_2D_t, implementation-data-type=sint32
      application-data-type=cif_0x0d7_Byte4_Bits67_t, implementation-data-type=uint8
      application-data-type=cif_0x0d7_Accuracy_INS_Vel_Body_org_t, implementation-data-type=uint8
      application-data-type=cif_0x0d7_INS_Vel_Forwards_2D_org_t, implementation-data-type=sint32
      application-data-type=cif_0x0d7_Accuracy_INS_Vel_Body_no2_t, implementation-data-type=uint8
      application-data-type=cif_0x0d7_INS_Vel_Forwards_2D_no2_t, implementation-data-type=sint32
      application-data-type=cif_0x0d7_Accuracy_INS_Vel_Body_no3_t, implementation-data-type=uint16
      application-data-type=cif_0x0d7_INS_Vel_Forwards_2D_no3_t, implementation-data-type=sint16
      application-data-type=cif_0x801024_Validity_Speed_t, implementation-data-type=boolean
      application-data-type=cif_0x801024_Accuracy_Speed_t, implementation-data-type=uint8
      application-data-type=cif_0x801024_Direction_t, implementation-data-type=uint8
      application-data-type=cif_0x801024_Speed_t, implementation-data-type=sint32
      application-data-type=cif_0x8c0124_Validity_GPS_Time_t, implementation-data-type=boolean
      application-data-type=cif_0x8c0124_Validity_GPS_Week_t, implementation-data-type=boolean
      application-data-type=cif_0x8c0124_Accuracy_GPS_Time_t, implementation-data-type=uint8
      application-data-type=cif_0x8c0124_GPS_Time_t, implementation-data-type=uint32
      application-data-type=cif_0x8c0124_GPS_Week_t, implementation-data-type=uint16
      application-data-type=cif_0x8c0324_GPS_Pos_LLH_Longitude_t, implementation-data-type=sint32
      application-data-type=cif_0x8c0324_GPS_Pos_LLH_Altitude_t, implementation-data-type=sint32
      application-data-type=cif_0x8c0224_Validity_GPS_Pos_LLH_Latitude_t, implementation-data-type=boolean
      application-data-type=cif_0x8c0224_Validity_GPS_Pos_LLH_Longitude_t, implementation-data-type=boolean
      application-data-type=cif_0x8c0224_Validity_GPS_Pos_LLH_Altitude_t, implementation-data-type=boolean
      application-data-type=cif_0x8c0224_Accuracy_GPS_Pos_LLH_Latitude_t, implementation-data-type=uint8
      application-data-type=cif_0x8c0224_Accuracy_GPS_Pos_LLH_Longitude_t, implementation-data-type=uint8
      application-data-type=cif_0x8c0224_Accuracy_GPS_Pos_LLH_Altitude_t, implementation-data-type=uint8
      application-data-type=cif_0x8c0224_GPS_Pos_LLH_Latitude_t, implementation-data-type=sint32
      application-data-type=cif_0x4d2_Validity_GPS_Speed_2D_t, implementation-data-type=boolean
      application-data-type=cif_0x4d2_Validity_GPS_Speed_3D_t, implementation-data-type=boolean
      application-data-type=cif_0x4d2_Accuracy_GPS_Speed_t, implementation-data-type=uint8
      application-data-type=cif_0x4d2_GPS_Speed_2D_t, implementation-data-type=uint32
      application-data-type=cif_0x4d2_GPS_Speed_3D_t, implementation-data-type=uint32
      application-data-type=cif_0x910725_IR_Temperature_7_t, implementation-data-type=sint16
      application-data-type=cif_0x980825_IR_Temperature_{29..32}_t, implementation-data-type=sint16
      application-data-type=cif_0x980625_IR_Temperature_{21..24}_t, implementation-data-type=sint16
      application-data-type=cif_0x980425_IR_Temperature_{13..16}_t, implementation-data-type=sint16
      application-data-type=cif_0x980225_IR_Temperature_{5..8}_t, implementation-data-type=sint16
      application-data-type=cif_0x980725_IR_Temperature_{25..28}_t, implementation-data-type=sint16
      application-data-type=cif_0x980525_IR_Temperature_{17..20}_t, implementation-data-type=sint16
      application-data-type=cif_0x980325_IR_Temperature_{9..12}_t, implementation-data-type=sint16
      application-data-type=cif_0x980125_IR_Temperature_{1..4}_t, implementation-data-type=sint16
      application-data-type=cif_0x912025_IR_Temperature_32_t, implementation-data-type=sint16
      application-data-type=cif_0x911f25_IR_Temperature_31_t, implementation-data-type=sint16
      application-data-type=cif_0x911e25_IR_Temperature_30_t, implementation-data-type=sint16
      application-data-type=cif_0x911d25_IR_Temperature_29_t, implementation-data-type=sint16
      application-data-type=cif_0x911c25_IR_Temperature_28_t, implementation-data-type=sint16
      application-data-type=cif_0x911b25_IR_Temperature_27_t, implementation-data-type=sint16
      application-data-type=cif_0x911a25_IR_Temperature_26_t, implementation-data-type=sint16
      application-data-type=cif_0x911925_IR_Temperature_25_t, implementation-data-type=sint16
      application-data-type=cif_0x911825_IR_Temperature_24_t, implementation-data-type=sint16
      application-data-type=cif_0x911625_IR_Temperature_22_t, implementation-data-type=sint16
      application-data-type=cif_0x911725_IR_Temperature_23_t, implementation-data-type=sint16
      application-data-type=cif_0x911525_IR_Temperature_21_t, implementation-data-type=sint16
      application-data-type=cif_0x911425_IR_Temperature_20_t, implementation-data-type=sint16
      application-data-type=cif_0x911325_IR_Temperature_19_t, implementation-data-type=sint16
      application-data-type=cif_0x911225_IR_Temperature_18_t, implementation-data-type=sint16
      application-data-type=cif_0x911025_IR_Temperature_16_t, implementation-data-type=sint16
      application-data-type=cif_0x910f25_IR_Temperature_15_t, implementation-data-type=sint16
      application-data-type=cif_0x910e25_IR_Temperature_14_t, implementation-data-type=sint16
      application-data-type=cif_0x910d25_IR_Temperature_13_t, implementation-data-type=sint16
      application-data-type=cif_0x910c25_IR_Temperature_12_t, implementation-data-type=sint16
      application-data-type=cif_0x910b25_IR_Temperature_11_t, implementation-data-type=sint16
      application-data-type=cif_0x910a25_IR_Temperature_10_t, implementation-data-type=sint16
      application-data-type=cif_0x910825_IR_Temperature_8_t, implementation-data-type=sint16
      application-data-type=cif_0x910925_IR_Temperature_9_t, implementation-data-type=sint16
      application-data-type=cif_0x911125_IR_Temperature_17_t, implementation-data-type=sint16
      application-data-type=cif_0x910625_IR_Temperature_6_t, implementation-data-type=sint16
      application-data-type=cif_0x910525_IR_Temperature_5_t, implementation-data-type=sint16
      application-data-type=cif_0x910425_IR_Temperature_4_t, implementation-data-type=sint16
      application-data-type=cif_0x910325_IR_Temperature_3_t, implementation-data-type=sint16
      application-data-type=cif_0x910225_IR_Temperature_2_t, implementation-data-type=sint16
      application-data-type=cif_0x910125_IR_Temperature_1_t, implementation-data-type=sint16
      application-data-type=cif_0x910125_CRC_t, implementation-data-type=uint8
      application-data-type=cif_0x8d0722_Validity_Final_Speed_t, implementation-data-type=boolean
      application-data-type=cif_0x8d0722_Final_Speed_t, implementation-data-type=uint32
      application-data-type=cif_0x31a_Validity_Initial_Speed_t, implementation-data-type=boolean
      application-data-type=cif_0x31a_Validity_Initial_Heading_t, implementation-data-type=boolean
      application-data-type=cif_0x31a_Initial_Speed_t, implementation-data-type=uint32
      application-data-type=cif_0x31a_Initial_Heading_t, implementation-data-type=sint16
      application-data-type=cif_0x31a_MFDD_Start_Threshold_t, implementation-data-type=uint8
      application-data-type=cif_0x31a_MFDD_End_Threshold_t, implementation-data-type=uint8
      application-data-type=cif_0x8d0522_Direct_Distance_t, implementation-data-type=uint32
      application-data-type=cif_0x8d0522_Path_Distance_2D_t, implementation-data-type=uint32
      application-data-type=cif_0x8d0422_Forward_Distance_t, implementation-data-type=sint32
      application-data-type=cif_0x8d0422_Deviation_Distance_t, implementation-data-type=sint32
      application-data-type=cif_0x8d0322_Path_Distance_3D_t, implementation-data-type=uint32
      application-data-type=cif_0x8d0222_Validity_MFDD_t, implementation-data-type=boolean
      application-data-type=cif_0x8d0222_Validity_Average_Accel_t, implementation-data-type=boolean
      application-data-type=cif_0x8d0222_Validity_Triggered_Time_t, implementation-data-type=boolean
      application-data-type=cif_0x8d0222_MFDD_t, implementation-data-type=sint16
      application-data-type=cif_0x8d0222_Average_Accel_t, implementation-data-type=sint16
      application-data-type=cif_0x8d0222_Triggered_Time_t, implementation-data-type=uint32
      application-data-type=cif_0x960c24_Measured_Time_12_t, implementation-data-type=uint32
      application-data-type=cif_0x960b24_Measured_Time_11_t, implementation-data-type=uint32
      application-data-type=cif_0x960a24_Measured_Time_10_t, implementation-data-type=uint32
      application-data-type=cif_0x960924_Measured_Time_9_t, implementation-data-type=uint32
      application-data-type=cif_0x960824_Measured_Time_8_t, implementation-data-type=uint32
      application-data-type=cif_0x960724_Measured_Time_7_t, implementation-data-type=uint32
      application-data-type=cif_0x960624_Measured_Time_6_t, implementation-data-type=uint32
      application-data-type=cif_0x960524_Measured_Time_5_t, implementation-data-type=uint32
      application-data-type=cif_0x960424_Measured_Time_4_t, implementation-data-type=uint32
      application-data-type=cif_0x960324_Measured_Time_3_t, implementation-data-type=uint32
      application-data-type=cif_0x960224_Measured_Time_2_t, implementation-data-type=uint32
      application-data-type=cif_0x960124_Measured_Time_1_t, implementation-data-type=uint32
      application-data-type=cif_0x950c24_RPM_t, implementation-data-type=uint16
      application-data-type=cif_0x950b24_Frequency_4_t, implementation-data-type=uint16
      application-data-type=cif_0x950a24_Frequency_3_t, implementation-data-type=uint16
      application-data-type=cif_0x950924_Frequency_2_t, implementation-data-type=uint16
      application-data-type=cif_0x970324_Misc_3_t, implementation-data-type=uint16
      application-data-type=cif_0x970224_Misc_2_t, implementation-data-type=uint16
      application-data-type=cif_0x970124_Misc_1_t, implementation-data-type=uint16
      application-data-type=cif_0x941f24_AUX_31_t, implementation-data-type=uint16
      application-data-type=cif_0x941e24_AUX_30_t, implementation-data-type=uint16
      application-data-type=cif_0x941d24_AUX_29_t, implementation-data-type=uint16
      application-data-type=cif_0x941c24_AUX_28_t, implementation-data-type=uint16
      application-data-type=cif_0x941b24_AUX_27_t, implementation-data-type=uint16
      application-data-type=cif_0x941a24_AUX_26_t, implementation-data-type=uint16
      application-data-type=cif_0x941924_AUX_25_t, implementation-data-type=uint16
      application-data-type=cif_0x941824_AUX_24_t, implementation-data-type=uint16
      application-data-type=cif_0x941724_AUX_23_t, implementation-data-type=uint16
      application-data-type=cif_0x941624_AUX_22_t, implementation-data-type=uint16
      application-data-type=cif_0x941524_AUX_21_t, implementation-data-type=uint16
      application-data-type=cif_0x941424_AUX_20_t, implementation-data-type=uint16
      application-data-type=cif_0x941324_AUX_19_t, implementation-data-type=uint16
      application-data-type=cif_0x941224_AUX_18_t, implementation-data-type=uint16
      application-data-type=cif_0x941124_AUX_17_t, implementation-data-type=uint16
      application-data-type=cif_0x941024_AUX_16_t, implementation-data-type=uint16
      application-data-type=cif_0x940f24_AUX_15_t, implementation-data-type=uint16
      application-data-type=cif_0x940e24_AUX_14_t, implementation-data-type=uint16
      application-data-type=cif_0x940d24_AUX_13_t, implementation-data-type=uint16
      application-data-type=cif_0x940c24_AUX_12_t, implementation-data-type=uint16
      application-data-type=cif_0x940b24_AUX_11_t, implementation-data-type=uint16
      application-data-type=cif_0x940924_AUX_9_t, implementation-data-type=uint16
      application-data-type=cif_0x940a24_AUX_10_t, implementation-data-type=uint16
      application-data-type=cif_0x940824_AUX_8_t, implementation-data-type=uint16
      application-data-type=cif_0x940724_AUX_7_t, implementation-data-type=uint16
      application-data-type=cif_0x940624_AUX_6_t, implementation-data-type=uint16
      application-data-type=cif_0x940524_AUX_5_t, implementation-data-type=uint16
      application-data-type=cif_0x940424_AUX_4_t, implementation-data-type=uint16
      application-data-type=cif_0x940324_AUX_3_t, implementation-data-type=uint16
      application-data-type=cif_0x940224_AUX_2_t, implementation-data-type=uint16
      application-data-type=cif_0x940124_AUX_1_t, implementation-data-type=uint16
      application-data-type=cif_0x900524_Pressure_5_t, implementation-data-type=uint32
      application-data-type=cif_0x900424_Pressure_4_t, implementation-data-type=uint32
      application-data-type=cif_0x900324_Pressure_3_t, implementation-data-type=uint32
      application-data-type=cif_0x900224_Pressure_2_t, implementation-data-type=uint32
      application-data-type=cif_0x900124_Pressure_1_t, implementation-data-type=uint32
      application-data-type=cif_0x920324_Angle_3_t, implementation-data-type=sint16
      application-data-type=cif_0x920224_Angle_2_t, implementation-data-type=sint16
      application-data-type=cif_0x920124_Angle_1_t, implementation-data-type=sint16
      application-data-type=cif_0x911924_Temperature_25_t, implementation-data-type=sint16
      application-data-type=cif_0x911824_Temperature_24_t, implementation-data-type=sint16
      application-data-type=cif_0x911724_Temperature_23_t, implementation-data-type=sint16
      application-data-type=cif_0x911624_Temperature_22_t, implementation-data-type=sint16
      application-data-type=cif_0x911524_Temperature_21_t, implementation-data-type=sint16
      application-data-type=cif_0x911424_Temperature_20_t, implementation-data-type=sint16
      application-data-type=cif_0x911324_Temperature_19_t, implementation-data-type=sint16
      application-data-type=cif_0x911224_Temperature_18_t, implementation-data-type=sint16
      application-data-type=cif_0x911124_Temperature_17_t, implementation-data-type=sint16
      application-data-type=cif_0x911024_Temperature_16_t, implementation-data-type=sint16
      application-data-type=cif_0x910f24_Temperature_15_t, implementation-data-type=sint16
      application-data-type=cif_0x910e24_Temperature_14_t, implementation-data-type=sint16
      application-data-type=cif_0x910d24_Temperature_13_t, implementation-data-type=sint16
      application-data-type=cif_0x910c24_Temperature_12_t, implementation-data-type=sint16
      application-data-type=cif_0x910b24_Temperature_11_t, implementation-data-type=sint16
      application-data-type=cif_0x910a24_Temperature_10_t, implementation-data-type=sint16
      application-data-type=cif_0x910924_Temperature_9_t, implementation-data-type=sint16
      application-data-type=cif_0x910824_Temperature_8_t, implementation-data-type=sint16
      application-data-type=cif_0x910724_Temperature_7_t, implementation-data-type=sint16
      application-data-type=cif_0x910624_Temperature_6_t, implementation-data-type=sint16
      application-data-type=cif_0x910524_Temperature_5_t, implementation-data-type=sint16
      application-data-type=cif_0x910424_Temperature_4_t, implementation-data-type=sint16
      application-data-type=cif_0x910324_Temperature_3_t, implementation-data-type=sint16
      application-data-type=cif_0x910224_Temperature_2_t, implementation-data-type=sint16
      application-data-type=cif_0x910124_Temperature_1_t, implementation-data-type=sint16
      application-data-type=cif_0x821f24_Analog_32_t, implementation-data-type=uint16
      application-data-type=cif_0x821e24_Analog_31_t, implementation-data-type=uint16
      application-data-type=cif_0x821d24_Analog_30_t, implementation-data-type=uint16
      application-data-type=cif_0x821c24_Analog_29_t, implementation-data-type=uint16
      application-data-type=cif_0x821b24_Analog_28_t, implementation-data-type=uint16
      application-data-type=cif_0x821a24_Analog_27_t, implementation-data-type=uint16
      application-data-type=cif_0x821924_Analog_26_t, implementation-data-type=uint16
      application-data-type=cif_0x821824_Analog_25_t, implementation-data-type=uint16
      application-data-type=cif_0x820e24_Analog_15_t, implementation-data-type=uint16
      application-data-type=cif_0x820d24_Analog_14_t, implementation-data-type=uint16
      application-data-type=cif_0x821024_Analog_17_t, implementation-data-type=uint16
      application-data-type=cif_0x821724_Analog_24_t, implementation-data-type=uint16
      application-data-type=cif_0x821624_Analog_23_t, implementation-data-type=uint16
      application-data-type=cif_0x821524_Analog_22_t, implementation-data-type=uint16
      application-data-type=cif_0x821424_Analog_21_t, implementation-data-type=uint16
      application-data-type=cif_0x821324_Analog_20_t, implementation-data-type=uint16
      application-data-type=cif_0x821224_Analog_19_t, implementation-data-type=uint16
      application-data-type=cif_0x820f24_Analog_16_t, implementation-data-type=uint16
      application-data-type=cif_0x821124_Analog_18_t, implementation-data-type=uint16
      application-data-type=cif_0x820b24_Analog_12_t, implementation-data-type=uint16
      application-data-type=cif_0x820a24_Analog_11_t, implementation-data-type=uint16
      application-data-type=cif_0x820924_Analog_10_t, implementation-data-type=uint16
      application-data-type=cif_0x820824_Analog_9_t, implementation-data-type=uint16
      application-data-type=cif_0x820724_Analog_8_t, implementation-data-type=uint16
      application-data-type=cif_0x820624_Analog_7_t, implementation-data-type=uint16
      application-data-type=cif_0x820524_Analog_6_t, implementation-data-type=uint16
      application-data-type=cif_0x820424_Analog_5_t, implementation-data-type=uint16
      application-data-type=cif_0x820324_Analog_4_t, implementation-data-type=uint16
      application-data-type=cif_0x820224_Analog_3_t, implementation-data-type=uint16
      application-data-type=cif_0x820124_Analog_2_t, implementation-data-type=uint16
      application-data-type=cif_0x820024_Analog_1_t, implementation-data-type=uint16
      application-data-type=cif_0x800024_Validity_Accel_Longitudinal_t, implementation-data-type=boolean
      application-data-type=cif_0x800024_Validity_Accel_Lateral_t, implementation-data-type=boolean
      application-data-type=cif_0x800024_Validity_Accel_Vertical_t, implementation-data-type=boolean
      application-data-type=cif_0x800024_SQC_t, implementation-data-type=uint8
      application-data-type=cif_0x800024_Accuracy_Accel_t, implementation-data-type=uint8
      application-data-type=cif_0x800024_Accel_Longitudinal_t, implementation-data-type=sint16
      application-data-type=cif_0x800024_Accel_Lateral_t, implementation-data-type=sint16
      application-data-type=cif_0x800024_Accel_Vertical_t, implementation-data-type=sint16
      application-data-type=cif_0x8f3222_Virtual_4_Vel_NED_D_t, implementation-data-type=sint32
      application-data-type=cif_0x8f3222_Virtual_4_Heading_t, implementation-data-type=sint16
      application-data-type=cif_0x8f3222_Virtual_4_Slip_t, implementation-data-type=sint16
      application-data-type=cif_0x8f3122_Virtual_4_Vel_NED_N_t, implementation-data-type=sint32
      application-data-type=cif_0x8f3122_Virtual_4_Vel_NED_E_t, implementation-data-type=sint32
      application-data-type=cif_0x8f3022_Virtual_4_Offset_X_t, implementation-data-type=sint16
      application-data-type=cif_0x8f3022_Virtual_4_Offset_Y_t, implementation-data-type=sint16
      application-data-type=cif_0x8f3022_Virtual_4_Offset_Z_t, implementation-data-type=sint16
      application-data-type=cif_0x8f2222_Virtual_3_Vel_NED_D_t, implementation-data-type=sint32
      application-data-type=cif_0x8f2222_Virtual_3_Heading_t, implementation-data-type=sint16
      application-data-type=cif_0x8f2222_Virtual_3_Slip_t, implementation-data-type=sint16
      application-data-type=cif_0x8f2122_Virtual_3_Vel_NED_N_t, implementation-data-type=sint32
      application-data-type=cif_0x8f2122_Virtual_3_Vel_NED_E_t, implementation-data-type=sint32
      application-data-type=cif_0x8f2022_Virtual_3_Offset_X_t, implementation-data-type=sint16
      application-data-type=cif_0x8f2022_Virtual_3_Offset_Y_t, implementation-data-type=sint16
      application-data-type=cif_0x8f2022_Virtual_3_Offset_Z_t, implementation-data-type=sint16
      application-data-type=cif_0x8f1222_Virtual_2_Vel_NED_D_t, implementation-data-type=sint32
      application-data-type=cif_0x8f1222_Virtual_2_Heading_t, implementation-data-type=sint16
      application-data-type=cif_0x8f1222_Virtual_2_Slip_t, implementation-data-type=sint16
      application-data-type=cif_0x8f1122_Virtual_2_Vel_NED_N_t, implementation-data-type=sint32
      application-data-type=cif_0x8f1122_Virtual_2_Vel_NED_E_t, implementation-data-type=sint32
      application-data-type=cif_0x8f1022_Virtual_2_Offset_X_t, implementation-data-type=sint16
      application-data-type=cif_0x8f1022_Virtual_2_Offset_Y_t, implementation-data-type=sint16
      application-data-type=cif_0x8f1022_Virtual_2_Offset_Z_t, implementation-data-type=sint16
      application-data-type=cif_0x8f0222_Virtual_1_Vel_NED_D_t, implementation-data-type=sint32
      application-data-type=cif_0x8f0222_Virtual_1_Heading_t, implementation-data-type=sint16
      application-data-type=cif_0x8f0222_Virtual_1_Slip_t, implementation-data-type=sint16
      application-data-type=cif_0x8f0122_Virtual_1_Vel_NED_N_t, implementation-data-type=sint32
      application-data-type=cif_0x8f0122_Virtual_1_Vel_NED_E_t, implementation-data-type=sint32
      application-data-type=cif_0x8f0022_Virtual_1_Offset_X_t, implementation-data-type=sint16
      application-data-type=cif_0x8f0022_Virtual_1_Offset_Y_t, implementation-data-type=sint16
      application-data-type=cif_0x8f0022_Virtual_1_Offset_Z_t, implementation-data-type=sint16
      application-data-type=cif_0x8e1622_Validity_INS_Slip_t, implementation-data-type=boolean
      application-data-type=cif_0x8e1622_Validity_INS_Squat_t, implementation-data-type=boolean
      application-data-type=cif_0x8e1622_Accuracy_INS_Slip_t, implementation-data-type=uint8
      application-data-type=cif_0x8e1622_INS_Slip_t, implementation-data-type=sint16
      application-data-type=cif_0x8e1622_Accuracy_INS_Squat_t, implementation-data-type=uint8
      application-data-type=cif_0x8e1622_INS_Squat_t, implementation-data-type=sint16
      application-data-type=cif_0x8e1322_Validity_INS_Vel_ECEF_Y_t, implementation-data-type=boolean
      application-data-type=cif_0x8e1322_Validity_INS_Vel_ECEF_Z_t, implementation-data-type=boolean
      application-data-type=cif_0x8e1322_INS_Vel_ECEF_Y_t, implementation-data-type=sint32
      application-data-type=cif_0x8e1322_INS_Vel_ECEF_Z_t, implementation-data-type=sint32
      application-data-type=cif_0x8e1222_Validity_INS_Vel_ECEF_X_t, implementation-data-type=boolean
      application-data-type=cif_0x8e1222_Accuracy_INS_Vel_ECEF_X_t, implementation-data-type=uint8
      application-data-type=cif_0x8e1222_Accuracy_INS_Vel_ECEF_Y_t, implementation-data-type=uint8
      application-data-type=cif_0x8e1222_Accuracy_INS_Vel_ECEF_Z_t, implementation-data-type=uint8
      application-data-type=cif_0x8e1222_INS_Vel_ECEF_X_t, implementation-data-type=sint32
      application-data-type=cif_0x8e1122_Validity_INS_Vel_NED_D_t, implementation-data-type=boolean
      application-data-type=cif_0x8e1122_Accuracy_INS_Vel_D_t, implementation-data-type=uint8
      application-data-type=cif_0x8e1122_INS_Vel_NED_D_t, implementation-data-type=sint32
      application-data-type=cif_0x8e1022_Validity_INS_Vel_NED_N_t, implementation-data-type=boolean
      application-data-type=cif_0x8e1022_Validity_INS_Vel_NED_E_t, implementation-data-type=boolean
      application-data-type=cif_0x8e1022_Accuracy_INS_Vel_NE_t, implementation-data-type=uint8
      application-data-type=cif_0x8e1022_INS_Vel_NED_N_t, implementation-data-type=sint32
      application-data-type=cif_0x8e1022_INS_Vel_NED_E_t, implementation-data-type=sint32
      application-data-type=cif_0x8e0522_INS_Pos_ECEF_Y_t, implementation-data-type=sint32
      application-data-type=cif_0x8e0522_INS_Pos_ECEF_Z_t, implementation-data-type=sint32
      application-data-type=cif_0x8e0422_Validity_INS_Pos_ECEF_X_t, implementation-data-type=boolean
      application-data-type=cif_0x8e0422_Validity_INS_Pos_ECEF_Y_t, implementation-data-type=boolean
      application-data-type=cif_0x8e0422_Validity_INS_Pos_ECEF_Z_t, implementation-data-type=boolean
      application-data-type=cif_0x8e0422_Accuracy_INS_Pos_ECEF_X_t, implementation-data-type=uint8
      application-data-type=cif_0x8e0422_Accuracy_INS_Pos_ECEF_Y_t, implementation-data-type=uint8
      application-data-type=cif_0x8e0422_Accuracy_INS_Pos_ECEF_Z_t, implementation-data-type=uint8
      application-data-type=cif_0x8e0422_INS_Pos_ECEF_X_t, implementation-data-type=sint32
      application-data-type=cif_0x8e0322_INS_Pos_LLH_Longitude_t, implementation-data-type=sint32
      application-data-type=cif_0x8e0322_INS_Pos_LLH_Altitude_t, implementation-data-type=sint32
      application-data-type=cif_0x8e0222_Validity_INS_Pos_LLH_Latitude_t, implementation-data-type=boolean
      application-data-type=cif_0x8e0222_Validity_INS_Pos_LLH_Longitude_t, implementation-data-type=boolean
      application-data-type=cif_0x8e0222_Validity_INS_Pos_LLH_Altitude_t, implementation-data-type=boolean
      application-data-type=cif_0x8e0222_Accuracy_INS_Pos_LLH_Latitude_t, implementation-data-type=uint8
      application-data-type=cif_0x8e0222_Accuracy_INS_Pos_LLH_Longitude_t, implementation-data-type=uint8
      application-data-type=cif_0x8e0222_Accuracy_INS_Pos_LLH_Altitude_t, implementation-data-type=uint8
      application-data-type=cif_0x8e0222_INS_Pos_LLH_Latitude_t, implementation-data-type=sint32
      application-data-type=cif_0x8e1522_Validity_INS_Heading_t, implementation-data-type=boolean
      application-data-type=cif_0x8e1522_Validity_INS_Gradient_t, implementation-data-type=boolean
      application-data-type=cif_0x8e1522_Accuracy_INS_Heading_t, implementation-data-type=uint8
      application-data-type=cif_0x8e1522_INS_Heading_2_t, implementation-data-type=uint16
      application-data-type=cif_0x8e1522_Accuracy_INS_Gradient_t, implementation-data-type=uint8
      application-data-type=cif_0x8e1522_INS_Gradient_t, implementation-data-type=sint16
      application-data-type=cif_0x8e1422_Validity_INS_Heading_t, implementation-data-type=boolean
      application-data-type=cif_0x8e1422_Validity_INS_Gradient_t, implementation-data-type=boolean
      application-data-type=cif_0x8e1422_Accuracy_INS_Heading_t, implementation-data-type=uint8
      application-data-type=cif_0x8e1422_INS_Heading_t, implementation-data-type=sint16
      application-data-type=cif_0x8e1422_Accuracy_INS_Gradient_t, implementation-data-type=uint8
      application-data-type=cif_0x8e1422_INS_Gradient_t, implementation-data-type=sint16
      application-data-type=cif_0x8e0022_INS_Status_t, implementation-data-type=uint8
      application-data-type=cif_0x8e0122_Validity_Yaw_t, implementation-data-type=boolean
      application-data-type=cif_0x8e0122_Validity_Pitch_t, implementation-data-type=boolean
      application-data-type=cif_0x8e0122_Validity_Roll_t, implementation-data-type=boolean
      application-data-type=cif_0x8e0122_Accuracy_Attitude_t, implementation-data-type=uint8
      application-data-type=cif_0x8e0122_Attitude_Yaw_t, implementation-data-type=sint16
      application-data-type=cif_0x8e0122_Attitude_Pitch_t, implementation-data-type=sint16
      application-data-type=cif_0x8e0122_Attitude_Roll_t, implementation-data-type=sint16
      application-data-type=cif_0x8d0122_Validity_Status_Timestamp_t, implementation-data-type=boolean
      application-data-type=cif_0x8d0122_Status_Analogue_{1..4}_t, implementation-data-type=boolean
      application-data-type=cif_0x8d0122_Status_Pulse_Output_t, implementation-data-type=boolean
      application-data-type=cif_0x8d0122_Status_Serial_Output_1_t, implementation-data-type=boolean
      application-data-type=cif_0x8d0122_Status_Serial_Output_2_t, implementation-data-type=boolean
      application-data-type=cif_0x8d0122_Status_Trigger_t, implementation-data-type=boolean
      application-data-type=cif_0x8d0122_GPS_Time_t, implementation-data-type=uint32
      application-data-type=cif_0x8c1622_Validity_GPS_Heading_t, implementation-data-type=boolean
      application-data-type=cif_0x8c1622_Validity_GPS_Gradient_t, implementation-data-type=boolean
      application-data-type=cif_0x8c1622_Accuracy_GPS_Heading_t, implementation-data-type=uint8
      application-data-type=cif_0x8c1622_GPS_Heading_2_t, implementation-data-type=uint16
      application-data-type=cif_0x8c1622_Accuracy_GPS_Gradient_t, implementation-data-type=uint8
      application-data-type=cif_0x8c1622_GPS_Gradient_t, implementation-data-type=sint16
      application-data-type=cif_0x802122_Validity_Cumulative_Time_t, implementation-data-type=boolean
      application-data-type=cif_0x802122_Validity_Cumulative_Distance_t, implementation-data-type=boolean
      application-data-type=cif_0x802122_Cumulative_Time_t, implementation-data-type=uint32
      application-data-type=cif_0x802122_Cumulative_Distance_t, implementation-data-type=uint32
      application-data-type=cif_0x802022_Validity_Cumulative_Time_t, implementation-data-type=boolean
      application-data-type=cif_0x802022_Validity_Cumulative_Distance_t, implementation-data-type=boolean
      application-data-type=cif_0x802022_Cumulative_Time_t, implementation-data-type=uint32
      application-data-type=cif_0x802022_Cumulative_Distance_t, implementation-data-type=uint32
      application-data-type=cif_0x8d0022_Validity_Trigger_Timestamp_t, implementation-data-type=boolean
      application-data-type=cif_0x8d0022_Accuracy_Trigger_Timestamp_t, implementation-data-type=uint8
      application-data-type=cif_0x8d0022_Trigger_Number_t, implementation-data-type=uint8
      application-data-type=cif_0x8d0022_Trigger_Timestamp_Type_t, implementation-data-type=boolean
      application-data-type=cif_0x8d0022_GPS_High_Resolution_Time_t, implementation-data-type=uint64
      application-data-type=cif_0x800121_Validity_Gyro_Rate_Yaw_t, implementation-data-type=boolean
      application-data-type=cif_0x800121_Validity_Gyro_Rate_Pitch_t, implementation-data-type=boolean
      application-data-type=cif_0x800121_Validity_Gyro_Rate_Roll_t, implementation-data-type=boolean
      application-data-type=cif_0x800121_Accuracy_Gyro_Rates_t, implementation-data-type=uint8
      application-data-type=cif_0x800121_Gyro_Rate_Yaw_t, implementation-data-type=sint16
      application-data-type=cif_0x800121_Gyro_Rate_Pitch_t, implementation-data-type=sint16
      application-data-type=cif_0x800121_Gyro_Rate_Roll_t, implementation-data-type=sint16
      application-data-type=cif_0x800021_Validity_Accel_Longitudinal_t, implementation-data-type=boolean
      application-data-type=cif_0x800021_Validity_Accel_Lateral_t, implementation-data-type=boolean
      application-data-type=cif_0x800021_Validity_Accel_Vertical_t, implementation-data-type=boolean
      application-data-type=cif_0x800021_Accuracy_Accel_t, implementation-data-type=uint8
      application-data-type=cif_0x800021_Accel_Longitudinal_t, implementation-data-type=sint16
      application-data-type=cif_0x800021_Accel_Lateral_t, implementation-data-type=sint16
      application-data-type=cif_0x800021_Accel_Vertical_t, implementation-data-type=sint16
      application-data-type=cif_0x801022_Validity_Speed_t, implementation-data-type=boolean
      application-data-type=cif_0x801022_Accuracy_Speed_t, implementation-data-type=uint8
      application-data-type=cif_0x801022_Speed_t, implementation-data-type=sint32
      application-data-type=cif_0x8c2122_Validity_RTK_Slip_t, implementation-data-type=boolean
      application-data-type=cif_0x8c2122_Validity_RTK_Squat_t, implementation-data-type=boolean
      application-data-type=cif_0x8c2122_Validity_RTK_Baseline_t, implementation-data-type=boolean
      application-data-type=cif_0x8c2122_Accuracy_RTK_Baseline_t, implementation-data-type=uint8
      application-data-type=cif_0x8c2122_RTK_Slip_t, implementation-data-type=sint16
      application-data-type=cif_0x8c2122_RTK_Squat_t, implementation-data-type=sint16
      application-data-type=cif_0x8c2122_RTK_Baseline_t, implementation-data-type=uint16
      application-data-type=cif_0x8c2022_Validity_RTK_Yaw_t, implementation-data-type=boolean
      application-data-type=cif_0x8c2022_Validity_RTK_Pitch_t, implementation-data-type=boolean
      application-data-type=cif_0x8c2022_Validity_RTK_Roll_t, implementation-data-type=boolean
      application-data-type=cif_0x8c2022_Accuracy_RTK_Attitude_t, implementation-data-type=uint8
      application-data-type=cif_0x8c2022_RTK_Attitude_Yaw_t, implementation-data-type=sint16
      application-data-type=cif_0x8c2022_RTK_Attitude_Pitch_t, implementation-data-type=sint16
      application-data-type=cif_0x8c2022_RTK_Attitude_Roll_t, implementation-data-type=sint16
      application-data-type=cif_0x8c3022_Validity_GPS_Lateral_Accel_t, implementation-data-type=boolean
      application-data-type=cif_0x8c3022_Validity_GPS_Mcycle_Lean_t, implementation-data-type=boolean
      application-data-type=cif_0x8c3022_Accuracy_GPS_Lateral_Accel_t, implementation-data-type=uint8
      application-data-type=cif_0x8c3022_GPS_Lateral_Accel_t, implementation-data-type=sint16
      application-data-type=cif_0x8c3022_GPS_Mcycle_Lean_Angle_t, implementation-data-type=sint16
      application-data-type=cif_0x8c0022_GPS_Status_t, implementation-data-type=uint8
      application-data-type=cif_0x8c0022_Firmware_Version_Major_t, implementation-data-type=uint8
      application-data-type=cif_0x8c0022_Firmware_Version_Intermediate_t, implementation-data-type=uint8
      application-data-type=cif_0x8c0022_Firmware_Version_Minor_t, implementation-data-type=uint8
      application-data-type=cif_0x8c0022_GPS_nSv_t, implementation-data-type=uint8
      application-data-type=cif_0x8c0022_GPS_nSv_2_t, implementation-data-type=uint8
      application-data-type=cif_0x8c0022_GPS_nSv_RTK_t, implementation-data-type=uint8
      application-data-type=cif_0x8c0022_RTK_Status_t, implementation-data-type=uint8
      application-data-type=cif_0x8c0522_GPS_Pos_ECEF_Y_t, implementation-data-type=sint32
      application-data-type=cif_0x8c0522_GPS_Pos_ECEF_Z_t, implementation-data-type=sint32
      application-data-type=cif_0x8c0422_Validity_GPS_Pos_ECEF_X_t, implementation-data-type=boolean
      application-data-type=cif_0x8c0422_Validity_GPS_Pos_ECEF_Y_t, implementation-data-type=boolean
      application-data-type=cif_0x8c0422_Validity_GPS_Pos_ECEF_Z_t, implementation-data-type=boolean
      application-data-type=cif_0x8c0422_Accuracy_GPS_Pos_ECEF_X_t, implementation-data-type=uint8
      application-data-type=cif_0x8c0422_Accuracy_GPS_Pos_ECEF_Y_t, implementation-data-type=uint8
      application-data-type=cif_0x8c0422_Accuracy_GPS_Pos_ECEF_Z_t, implementation-data-type=uint8
      application-data-type=cif_0x8c0422_GPS_Pos_ECEF_X_t, implementation-data-type=sint32
      application-data-type=cif_0x8c0322_GPS_Pos_LLH_Longitude_t, implementation-data-type=sint32
      application-data-type=cif_0x8c0322_GPS_Pos_LLH_Altitude_t, implementation-data-type=sint32
      application-data-type=cif_0x8c0222_Validity_GPS_Pos_LLH_Latitude_t, implementation-data-type=boolean
      application-data-type=cif_0x8c0222_Validity_GPS_Pos_LLH_Longitude_t, implementation-data-type=boolean
      application-data-type=cif_0x8c0222_Validity_GPS_Pos_LLH_Altitude_t, implementation-data-type=boolean
      application-data-type=cif_0x8c0222_Accuracy_GPS_Pos_LLH_Latitude_t, implementation-data-type=uint8
      application-data-type=cif_0x8c0222_Accuracy_GPS_Pos_LLH_Longitude_t, implementation-data-type=uint8
      application-data-type=cif_0x8c0222_Accuracy_GPS_Pos_LLH_Altitude_t, implementation-data-type=uint8
      application-data-type=cif_0x8c0222_GPS_Pos_LLH_Latitude_t, implementation-data-type=sint32
      application-data-type=cif_0x8c1522_Validity_GPS_Heading_t, implementation-data-type=boolean
      application-data-type=cif_0x8c1522_Validity_GPS_Gradient_t, implementation-data-type=boolean
      application-data-type=cif_0x8c1522_Accuracy_GPS_Heading_t, implementation-data-type=uint8
      application-data-type=cif_0x8c1522_GPS_Heading_t, implementation-data-type=sint16
      application-data-type=cif_0x8c1522_Accuracy_GPS_Gradient_t, implementation-data-type=uint8
      application-data-type=cif_0x8c1522_GPS_Gradient_t, implementation-data-type=sint16
      application-data-type=cif_0x8c1422_Validity_GPS_Vel_ECEF_Y_t, implementation-data-type=boolean
      application-data-type=cif_0x8c1422_Validity_GPS_Vel_ECEF_Z_t, implementation-data-type=boolean
      application-data-type=cif_0x8c1422_GPS_Vel_ECEF_Y_t, implementation-data-type=sint32
      application-data-type=cif_0x8c1422_GPS_Vel_ECEF_Z_t, implementation-data-type=sint32
      application-data-type=cif_0x8c1322_Validity_GPS_Vel_ECEF_X_t, implementation-data-type=boolean
      application-data-type=cif_0x8c1322_Accuracy_GPS_Vel_ECEF_X_t, implementation-data-type=uint8
      application-data-type=cif_0x8c1322_Accuracy_GPS_Vel_ECEF_Y_t, implementation-data-type=uint8
      application-data-type=cif_0x8c1322_Accuracy_GPS_Vel_ECEF_Z_t, implementation-data-type=uint8
      application-data-type=cif_0x8c1322_GPS_Vel_ECEF_X_t, implementation-data-type=sint32
      application-data-type=cif_0x000_Validity_GPS_Vel_NED_D_t, implementation-data-type=boolean
      application-data-type=cif_0x000_Accuracy_GPS_Vel_D_t, implementation-data-type=uint8
      application-data-type=cif_0x000_GPS_Vel_NED_D_t, implementation-data-type=sint32
      application-data-type=cif_0x1fffffff_Validity_GPS_Vel_NED_N_t, implementation-data-type=boolean
      application-data-type=cif_0x1fffffff_Validity_GPS_Vel_NED_E_t, implementation-data-type=boolean
      application-data-type=cif_0x1fffffff_Accuracy_GPS_Vel_NE_t, implementation-data-type=uint8
      application-data-type=cif_0x1fffffff_GPS_Vel_NED_N_t, implementation-data-type=sint32
      application-data-type=cif_0x1fffffff_GPS_Vel_NED_E_t, implementation-data-type=sint32
      application-data-type=cif_0x71a_Validity_GPS_Speed_2D_t, implementation-data-type=boolean
      application-data-type=cif_0x71a_Validity_GPS_Speed_3D_t, implementation-data-type=boolean
      application-data-type=cif_0x71a_Accuracy_GPS_Speed_t, implementation-data-type=uint8
      application-data-type=cif_0x71a_GPS_Speed_2D_t, implementation-data-type=uint32
      application-data-type=cif_0x71a_GPS_Speed_3D_t, implementation-data-type=uint32
      application-data-type=cif_0x7ff_Validity_GPS_Time_t, implementation-data-type=boolean
      application-data-type=cif_0x7ff_Validity_GPS_Week_t, implementation-data-type=boolean
      application-data-type=cif_0x7ff_Accuracy_GPS_Time_t, implementation-data-type=uint8
      application-data-type=cif_0x7ff_GPS_Time_t, implementation-data-type=uint32
      application-data-type=cif_0x7ff_GPS_Week_t, implementation-data-type=uint16
      application-data-type=cif_0x122_Validity_Accel_Longitudinal_t, implementation-data-type=boolean
      application-data-type=cif_0x122_Validity_Accel_Lateral_t, implementation-data-type=boolean
      application-data-type=cif_0x122_Validity_Accel_Vertical_t, implementation-data-type=boolean
      application-data-type=cif_0x122_Accuracy_Accel_t, implementation-data-type=uint8
      application-data-type=cif_0x122_Accel_Longitudinal_t, implementation-data-type=sint16
      application-data-type=cif_0x122_Accel_Lateral_t, implementation-data-type=sint16
      application-data-type=cif_0x122_Accel_Vertical_t, implementation-data-type=sint16
      application-data-type=cif_0x800122_Validity_Gyro_Rate_Yaw_t, implementation-data-type=boolean
      application-data-type=cif_0x800122_Validity_Gyro_Rate_Pitch_t, implementation-data-type=boolean
      application-data-type=cif_0x800122_Validity_Gyro_Rate_Roll_t, implementation-data-type=boolean
      application-data-type=cif_0x800122_Accuracy_Gyro_Rates_t, implementation-data-type=uint8
      application-data-type=cif_0x800122_Gyro_Rate_Yaw_t, implementation-data-type=sint16
      application-data-type=cif_0x800122_Gyro_Rate_Pitch_t, implementation-data-type=sint16
      application-data-type=cif_0x800122_Gyro_Rate_Roll_t, implementation-data-type=sint16
package /cif_swcCanInterface/CANBus_CAN_RT  # This package contains the frame related interface specifications and signal related data type specifications for CAN bus CAN_RT. They are held in two dedicated sub-folders. Only those frames and signals are considered, which are either sent or received by the modeled network node ECU.
package /cif_swcCanInterface/CANBus_CAN_RT/applicationDataTypes  # This package contains an application data type definition for each signal appearing in bus CAN_RT. The data type object is completed by a compu-method object holding the scaling information and a data constraint object holding the signal's world value range
  app type cif_0x0d7_Validity_INS_Vel_Forwards_t:  # The type of CAN input signal Validity_INS_Vel_Forwards, frame RT_SB_INS_Vel_Body_Axes, 215 (0x0d7). Implementation type is boolean
    category=VALUE
    compu {phys=raw} "The scaling of CAN input signal Validity_INS_Vel_Forwards, frame RT_SB_INS_Vel_Body_Axes, 215 (0x0d7). Scaling: WorldValue = BinaryValue []. Unit: The unit "" from the network database is mapped to the AUTOSAR unit NoUnit"
    range phys 0..1 "The range of CAN input signal Validity_INS_Vel_Forwards, frame RT_SB_INS_Vel_Body_Axes, 215 (0x0d7). Range (world values): 0.0 ... 1.0 []"
